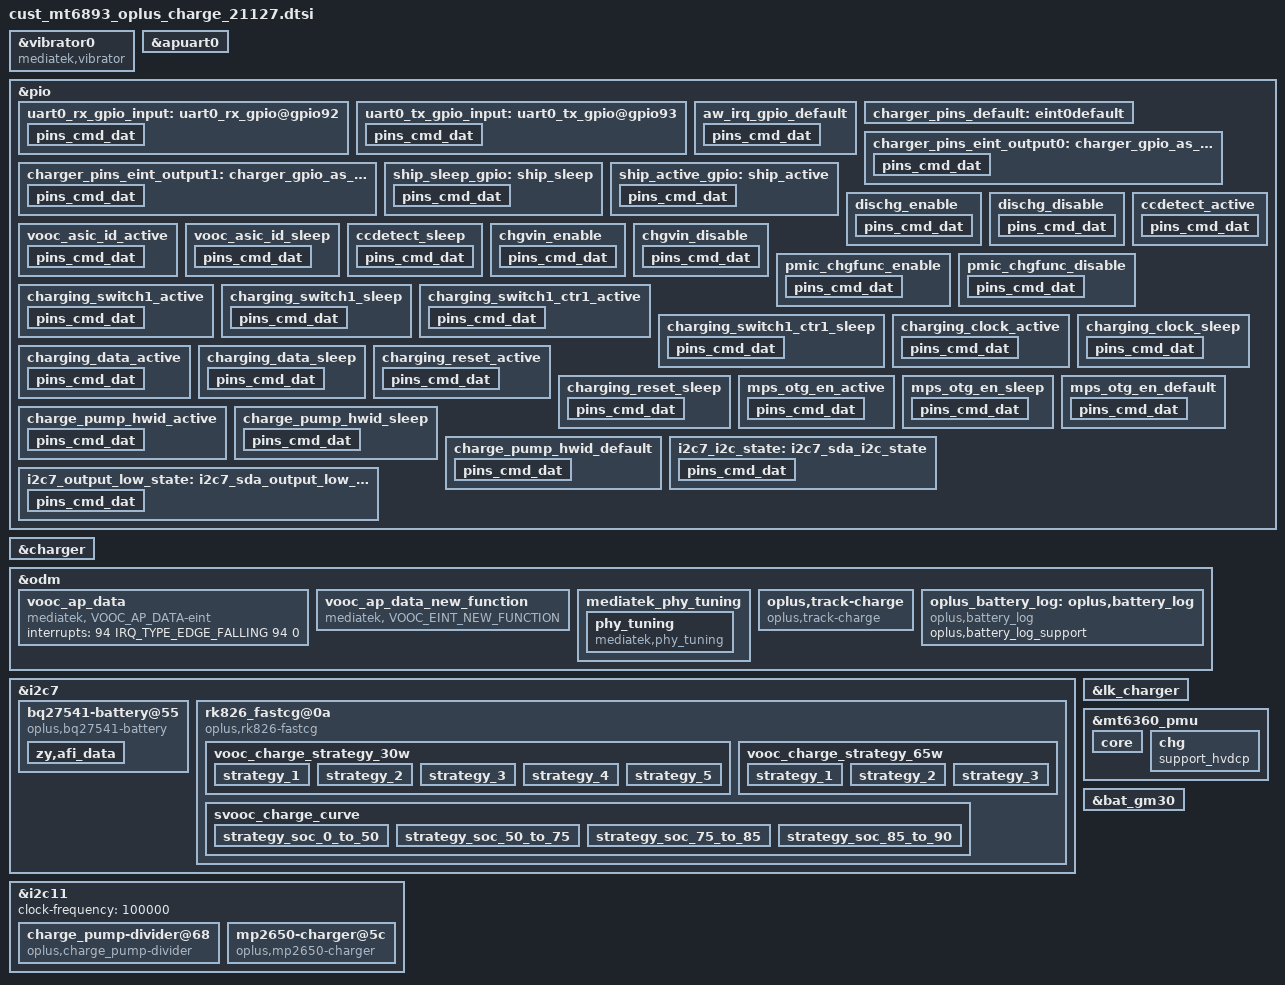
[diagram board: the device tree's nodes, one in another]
// SPDX-License-Identifier: GPL-2.0-only
/*
* Copyright (C) 2021-2020 Oplus. All rights reserved.
*/

/* charge start */
&vibrator0 {
	compatible = "mediatek,vibrator";
	vib_timer = <30>;
	vib_limit = <0>;
	vib_vol= <11>;
	lk_vib_vol  = <11>;
	status = "okay";
};

&apuart0 {
	pinctrl-names = "uart0_rx_gpio", "uart0_tx_gpio";
	pinctrl-0 = <&uart0_rx_gpio_input>;
	pinctrl-1 = <&uart0_tx_gpio_input>;
	status = "okay";
};

&pio {
	uart0_rx_gpio_input:uart0_rx_gpio@gpio92 {
		pins_cmd_dat {
			pinmux = <PINMUX_GPIO92__FUNC_GPIO92>;
			input-enable;
			slew-rate = <0>;
			bias-disable;
		};
	};

	uart0_tx_gpio_input:uart0_tx_gpio@gpio93 {
		pins_cmd_dat {
			pinmux = <PINMUX_GPIO93__FUNC_GPIO93>;
			input-enable;
			slew-rate = <0>;
			bias-disable;
		};
	};
};

&charger {
	io-channels = <&auxadc 4>,
		<&auxadc 5>;
	io-channel-names = "auxadc4-usb_temp_v_l",
		"auxadc5-usb_temp_v_r";

	pinctrl-names = "default", "charger_gpio_as_output_low", "charger_gpio_as_output_high", "ship_sleep", "ship_active",
		"dischg_enable", "dischg_disable", "chgvin_enable", "chgvin_disable", "pmic_chgfunc_enable", "pmic_chgfunc_disable",
		"ccdetect_active","ccdetect_sleep";
	pinctrl-0 = <&charger_pins_default>;
	pinctrl-1 = <&charger_pins_eint_output0>;		//USB_ON -> USB_SWITCH:(UART && USB)
	pinctrl-2 = <&charger_pins_eint_output1>;
	pinctrl-3 = <&ship_sleep_gpio>;
	pinctrl-4 = <&ship_active_gpio>;
	pinctrl-5 = <&dischg_enable>;
	pinctrl-6 = <&dischg_disable>;
	pinctrl-7 = <&chgvin_enable>;
	pinctrl-8 = <&chgvin_disable>;
	pinctrl-9 = <&pmic_chgfunc_enable>;
	pinctrl-10 = <&pmic_chgfunc_disable>;
	//pinctrl-5 = <&shortc_active_gpio>;
	pinctrl-11 = <&ccdetect_active>;
	pinctrl-12 = <&ccdetect_sleep>;

	qcom,hv_flashled_support;
	qcom,chargerid_support;
	qcom,smart_charging_screenoff;
	qcom,usbtemp_batttemp_gap = <12>;
	qcom,input_current_charger_ma = <2000>;
	qcom,pd_input_current_charger_ma = <2000>;
	qcom,qc_input_current_charger_ma = <2000>;
	qcom,input_current_usb_ma = <500>;

	qcom,input_current_led_ma = <1200>;
	qcom,input_current_led_ma_high = <1200>;
	qcom,input_current_led_ma_warm = <1500>;
	qcom,input_current_led_ma_normal = <2000>;
	qcom,led_warm_bat_decidegc = <350>;
	qcom,led_high_bat_decidegc = <370>;

	qcom,input_current_camera_ma = <1200>;
	qcom,input_current_cdp_ma = <1500>;

	qcom,input_current_vooc_led_ma_high = <2200>;
	qcom,input_current_vooc_led_ma_warm = <3200>;
	qcom,input_current_vooc_led_ma_normal = <3600>;
	qcom,input_current_vooc_ma_normal = <3600>;
	qcom,vooc_temp_bat_normal_decidegc = <350>;
	qcom,input_current_vooc_ma_warm = <3200>;
	qcom,vooc_temp_bat_warm_decidegc = <370>;
	qcom,input_current_vooc_ma_high = <2200>;
	qcom,vooc_temp_bat_hot_decidegc = <510>;

	qcom,charger_current_vooc_ma_normal = <1800>;

	qcom,chg_ctrl_by_calling;
	qcom,input_current_calling_ma = <1500>;

	qcom,overtemp_bat_decidegc = <350>;
	qcom,iterm_disabled = <0>;
	sw_full_count = <25>;
	qcom,iterm_ma = <230>;
	qcom,recharge-mv = <100>;
	qcom,batt_capacity_mah = <4500>;/*typical capacity*/

	qcom,removed_bat_decidegc = <190>;  /*<-19C*/

	qcom,cold_bat_decidegc = <100>;  /*-10C~0C*/
	qcom,temp_cold_vfloat_mv = <4438>;
	qcom,temp_cold_fastchg_current_ma = <550>;

	qcom,little_cold_bat_decidegc = <0>;    /*0C~5C*/
	qcom,temp_little_cold_vfloat_mv = <4438>;
	qcom,temp_little_cold_fastchg_current_ma_high = <1100>;
	qcom,temp_little_cold_fastchg_current_ma_low = <1100>;
	qcom,temp_little_cold_fastchg_current_ma = <1100>;
	qcom,pd_temp_little_cold_fastchg_current_ma_high = <2000>;
	qcom,pd_temp_little_cold_fastchg_current_ma_low = <1430>;
	qcom,qc_temp_little_cold_fastchg_current_ma_high = <2000>;
	qcom,qc_temp_little_cold_fastchg_current_ma_low = <1430>;

	qcom,cool_bat_decidegc = <50>;  /*5C~12C*/
	qcom,temp_cool_vfloat_mv = <4438>;
	qcom,temp_cool_fastchg_current_ma_high = <1100>;
	qcom,temp_cool_fastchg_current_ma_low = <1100>;
	qcom,pd_temp_cool_fastchg_current_ma_high = <2000>;
	qcom,pd_temp_cool_fastchg_current_ma_low = <2000>;
	qcom,qc_temp_cool_fastchg_current_ma_high = <2000>;
	qcom,qc_temp_cool_fastchg_current_ma_low = <2000>;

	qcom,little_cool_bat_decidegc = <120>;  /*12C~16C*/
	qcom,temp_little_cool_vfloat_mv = <4438>;
	qcom,temp_little_cool_fastchg_current_ma = <1100>;
	qcom,pd_temp_little_cool_fastchg_current_ma = <2000>;
	qcom,qc_temp_little_cool_fastchg_current_ma = <2000>;

	qcom,normal_bat_decidegc = <160>;       /*16C~45C*/
	qcom,temp_normal_vfloat_mv = <4438>;
	qcom,temp_normal_fastchg_current_ma = <1100>;
	qcom,pd_temp_normal_fastchg_current_ma = <2000>;
	qcom,qc_temp_normal_fastchg_current_ma = <2000>;

	qcom,warm_bat_decidegc = <450>;         /*45C~53C*/ /*8pin Bat Vooc project need add 3 degree C*/
	qcom,temp_warm_vfloat_mv = <4130>;
	qcom,temp_warm_fastchg_current_ma = <1100>;
	qcom,pd_temp_warm_fastchg_current_ma = <1210>;
	qcom,qc_temp_warm_fastchg_current_ma = <1210>;
	qcom,temp_warm_fastchg_current_ma_led_on = <500>;

	qcom,hot_bat_decidegc = <530>;

	qcom,non_standard_vfloat_mv = <3980>;
	qcom,non_standard_fastchg_current_ma = <512>;

	qcom,short_c_bat_cv_mv = <4330>;
	qcom,short_c_bat_vfloat_mv = <3800>;
	qcom,short_c_bat_fastchg_current_ma = <512>;

	qcom,cold_vfloat_sw_limit = <4385>;
	qcom,little_cold_vfloat_sw_limit = <4385>;
	qcom,cool_vfloat_sw_limit = <4385>;
	qcom,little_cool_vfloat_sw_limit = <4385>;
	qcom,normal_vfloat_sw_limit = <4385>;
	qcom,warm_vfloat_sw_limit = <4080>;
	qcom,non_standard_vfloat_sw_limit = <3930>;
	qcom,short_c_bat_vfloat_sw_limit = <3750>;

	qcom,max_chg_time_sec = <63360>; // 2200 * 2 / 250 H
	qcom,charger_hv_thr = <9900>;
	qcom,charger_recv_thr = <9500>;
	qcom,charger_lv_thr = <3400>;
	qcom,vbatt_full_thr = <4438>;
	qcom,vbatt_hv_thr = <4600>;

	qcom,vfloat_step_mv = <8>;
	qcom,non_standard_vfloat_over_sw_limit = <3990>;
	qcom,cold_vfloat_over_sw_limit = <4445>;
	qcom,little_cold_vfloat_over_sw_limit = <4445>;
	qcom,cool_vfloat_over_sw_limit = <4445>;
	qcom,little_cool_vfloat_over_sw_limit = <4445>;
	qcom,normal_vfloat_over_sw_limit = <4445>;
	qcom,warm_vfloat_over_sw_limit = <4140>;

	qcom,vbatt_power_off = <3300>;
	qcom,vbatt_soc_1 = <3310>;
	qcom,vooc_project = <7>;
	qcom,vbatt_num = <2>;
	qcom,new_ui_warning_support;
	qcom,ffc_support;
	qcom,dual_ffc;

	qcom,normal_vterm_hw_inc = <18>;
	qcom,non_normal_vterm_hw_inc = <18>;

	qcom,ff1_normal_fastchg_ma = <550>;
	qcom,ff1_warm_fastchg_ma = <550>;

	qcom,ffc2_normal_fastchg_ma = <350>;/*12C~35c*/
	qcom,ffc2_temp_warm_decidegc = <350>;
	qcom,ffc2_warm_fastchg_ma = <350>;/*35C~40c*/
	qcom,ffc2_temp_high_decidegc = <400>;
	qcom,ffc2_temp_low_decidegc = <120>;

	qcom,ff1_exit_step_ma = <150>;
	qcom,ff1_warm_exit_step_ma = <150>;
	qcom,ffc2_exit_step_ma = <150>;
	qcom,ffc2_warm_exit_step_ma = <150>;

	qcom,ffc_normal_vfloat_sw_limit = <4445>;
	qcom,ffc_temp_normal_vfloat_mv = <4500>;
	qcom,ffc_normal_vfloat_over_sw_limit = <4500>;
	qcom,ffc_warm_vfloat_sw_limit = <4445>;
	qcom,ffc_temp_warm_vfloat_mv = <4500>;
	qcom,ffc_warm_vfloat_over_sw_limit = <4500>;

	qcom,ffc2_normal_vfloat_sw_limit = <4440>;
	qcom,ffc2_temp_normal_vfloat_mv = <4500>;
	qcom,ffc2_normal_vfloat_over_sw_limit = <4500>;
	qcom,ffc2_warm_vfloat_sw_limit = <4438>;
	qcom,ffc2_temp_warm_vfloat_mv = <4500>;
	qcom,ffc2_warm_vfloat_over_sw_limit = <4500>;

	qcom,default_iterm_ma = <230>;
	qcom,default_temp_normal_fastchg_current_ma = <1100>;
	qcom,default_normal_vfloat_sw_limit = <4385>;
	qcom,default_temp_normal_vfloat_mv = <4438>;
	qcom,default_normal_vfloat_over_sw_limit = <4445>;

	qcom,default_temp_little_cool_fastchg_current_ma = <1100>;
	qcom,default_little_cool_vfloat_sw_limit = <4385>;
	qcom,default_temp_little_cool_vfloat_mv = <4438>;
	qcom,default_little_cool_vfloat_over_sw_limit = <4445>;

	qcom,vooc_show_ui_soc_decimal;
	qcom,ui_soc_decimal_speedmin = <20>;//2A
	qcom,check_batt_full_by_sw;
	qcom,external_gauge;
	qcom,chg_ctrl_by_lcd;
	qcom,chg_ctrl_by_vooc;
	qcom,chg_ctrl_by_camera;
	qcom,support_ntc_01c_precision;
	qcom,sw_vfloat_over_protect_enable;

	qcom,support_abnormal_adapter;

	//for PD9V or QC9V
	qcom,vbatt_pdqc_to_5v_thr = <4100>;
	qcom,vbatt_pdqc_to_9v_thr = <4000>;

	//GPIO config:
	qcom,chargerid_switch-gpio = <&pio 192 0x00>;
	qcom,ship-gpio = <&pio 27 0x00>;
	qcom,dischg-gpio = <&pio 51 0x00>;
	//qcom,shortc-gpio = <&pio 121 0x00>;
	qcom,ccdetect-gpio = <&pio 5 0x00>;
	qcom,chgvin = <&pio 30 0x00>;
	qcom,pmic_chgfunc = <&pio 26 0x00>;
};

&pio{
	aw_irq_gpio_default: aw_irq_gpio_default {
		pins_cmd_dat {
			pinmux = <PINMUX_GPIO8__FUNC_GPIO8>;
			input-enable;
			slew-rate = <0>;
			bias-pull-up;
		};
	};
};

&odm {
	vooc_ap_data:vooc_ap_data {
		compatible = "mediatek, VOOC_AP_DATA-eint";
		interrupts = <94 IRQ_TYPE_EDGE_FALLING 94 0>;
	};
	vooc_ap_data_new_function:vooc_ap_data_new_function {
		compatible = "mediatek, VOOC_EINT_NEW_FUNCTION";
	};

	mediatek_phy_tuning:mediatek_phy_tuning {
		phy_tuning {
			compatible = "mediatek,phy_tuning";
			eye-vrt = <6>;
			eye-term = <6>;
			eye-rev6 = <2>;
			eye-disc = <0xF>;
			host-eye-vrt = <6>;
			host-eye-term = <6>;
			host-eye-rev6 = <2>;
			host-eye-disc = <0xF>;
		};
	};

	oplus,track-charge {
		compatible = "oplus,track-charge";
		track,fast_chg_break_t_thd = <1000>;
		track,general_chg_break_t_thd = <200>;
		track,voocphy_type = <4>;
		track,wired_max_power = <80000>;
		track,wired_fast_chg_scheme = <1>;
	};

	oplus_battery_log: oplus,battery_log {
		compatible = "oplus,battery_log";
		oplus,battery_log_support;
	};
};

&i2c7 {
	status = "okay";
	clock-frequency = <100000>;

	bq27541-battery@55 {
		status = "okay";
		compatible = "oplus,bq27541-battery";
		reg = <0x55 0>;
		qcom,modify-soc-smooth;
		qcom,modify-soc-calibration;
		qcom,batt_bq28z610;
		qcom,sha1_key_index = <1>;
		//qcom,bq28z610_need_balancing;
		zy,afi_data{
			battery,name = "BLP855";
			qmax_min = <1776>;
			qmax_max = <2553>;
			static_df_checksum_3e = [38 68];			//len 2
			static_df_checksum_60 = [A3 06];			//len 2
			afi_buf_num = <7>;
			afi_buf_0 = [
				11 D0 11 17 11 D0 11 17 11 D0 11 17 11 D0 11 17 
				01 0A 8C 0A 0C 1C 25 1C 02 FF CE 02 EC 78 02 FF
				CE 05 C2 0A C2 0A 72 A3 0A 0C D1 02 0C 9F 0D 03 
				02 0C D1 0A 79 02 0A AB 09 E3 02 0A 15 07 D0 07 
				08 07 08 00 02 09 C4 07 D0 D2 F0 00 02 03 E8 05 
				11 EE 05 0E 74 00 0A 01 F4 0A 07 08 0E 74 00 0A 
				01 F4 0A 00 0A 05 FF F6 05 0A 0A AB 0B 23 0B 73 
				0B A5 0B D7 0C D1 00 0A 00 58 00 2C 11 5D 00 84 
				01 60 01 08 11 5D 07 BC 0F A4 0B B0 11 5D 09 CC 
				11 88 0D C0 11 5D 03 F4 07 BC 05 D8 09 C4 0D 48 
				0E D8 0F A0 00 01 01 2C 01 2C 01 2C 01 2C 00 4B 
				03 84 28 01 65 01 6B 03 00 00 46 50 50 00 30 00
				96 00 AF 08 AC 06 B6 1E 3C 5A
				];
			afi_buf_1 = [
				64 63 64 61 00 01 01 02 05 21 1C 00 A2 40 00 17 
				00 00 00 03 00 00 0A F0 0A 28 14 0A 14 10 E0 64 
				07 D0 00 03 0F 00 14 04 19 C8 00
				];
			afi_buf_2 = [
				AA 21 10 03 43 05 41 07 21 09 81 0B EB 0D E7 0F 
				19 11 3B 13 9E 15 FC 17 74 19 6A 1B 64 5D B2 B5 
				00 33 22 04 24 22 26 8F 28 62 2A CC 2C E4 2E 46 
				30 58 32 79 34 9F 36 1B 38 49 3A 03 7C 56 08 D7 
				08 D6 33
				];
			afi_buf_3 = [
				11 38 11 38 01 2C FE D5 FC 18 FE D5 FC 18 00 5D 
				00 32 00 32
				];
			afi_buf_4 = [38 68];
			afi_buf_5 = [
				FF 21 10 03 43 05 41 07 21 09 81 0B EB 0D E7 0F 
				19 11 3B 13 9E 15 FC 17 74 19 6A 1B 64 5D B2 E0 
				00 33 22 04 24 22 26 8F 28 62 2A CC 2C E4 2E 46 
				30 58 32 79 34 9F 36 1B 38 49 3A 03 7C 56 01 01 
				00 00 00 00 00 14 00 0F 00 46 00 3C 00 3C 01 3C 
				FF F6 FE 0C 32
				];
			afi_buf_6 = [
				2A 69 20 A8 26 82 24 64 2A 09 08 77 0E 75 0C 9B 
				12 81 10 BF 16 9D 14 F3 1A 58 FB C6 FD 47 FF 28 
				C1 35 C3 12 C5 8B C7 4D C9 2F CB C8 CD CC CF 6F 
				F1 EF F3 4E F5 69 F7 4C F9 43 FB 82 FD C5 FF 48 
				81 57 83 17 85 97 87 E8 89 A7 8B 05 8D 81 EF F7 
				31 E9 CD 75 CB 11 C9 DB 27 47 C5 3A C3 D3 C1 AB 
				FF 72 FD 95 DB B3 D9 B6 D7 39 D5 16 B3 06 B1 3F 
				8F 1B AD 05 CB DE A9 CD 78 D6 7A 0C 7C 6A 5E FC 
				80 9E A2 CA 84 37 86 BF 88 CE 35 45 D3 5A B1 77 
				AF 19 AD 08 AB 67 C9 EB E7 88 E5 E6 83 3C 20 7E 
				C0 A1 5D E5 5B CC 59 2A 57 04 55 4A 53 A1 51 C2 
				4F 7F 4D 23 4B 05 49 D9 47 68 45 20 BC F3 41 E0 
				1F 2F 1D D3 1B D6 19 34 37 EB 15 5D 13 37 11 A0 
				0F 7B 0D 9A 0B 9E 09 F0 07 59 05 38 03 88 FE 5A 
				E0 E1 E2 20 E4 26 E6 FE C8 6C 8A EB AC AC ED EB 
				90 10 B3 F3 78 F5 B6 D4 E1 38 46 3A 50 DD EC FF 
				8C 21 62 A3 A4 A1 CE 07 8A 05 4B 28 09 81 4E 04 
				10 51 12 13 75 02 36 92 5E 5F 5B 5B 7C 5D 5F 5E 
				61 67 E3 83 A4 CA 86 A5 28 30 6A BC EC 2D 2E AD 
				54 31 2B 73 E9 16 BA 76 58 69 DC FB 93 3D 3E DE 
				B0 41 A3 A3 3C 45 46 47 48 49 A7 2A 05 4D E2 6E 
				19 51 B7 73 7D 55 B7 57 70 59 B9 BA 14 5D 5E 5F 
				60 61 62 63 64 65 C7 86 21 69 4B AA A4 6D 6E 6F 
				70 71 72 73 74 75 76 77 78 79 7A 7B 7C 7D 7E 7F 
				80 01 02 83 E4 C5 C6 87 C8 89 8A 8B 8C 8D 4F 8D 
				90 9E FC 99 D4 74 B6 85 98 80 9A 82 1C 9D 5D FF 
				A0 2D A2 FC 04 29 A6 BE C8 89 61 AB F3 2F 8E BD 
				15 3D 12 F8 14 B5 B6 B7 0C B2 0C E4 0A 5F 01 2C
				];
		};
	};

	rk826_fastcg@0a{
		status = "okay";
		compatible = "oplus,rk826-fastcg";
		reg = <0x0a 0>;
		qcom,oplus_batt_4250mv;
		qcom,support_vooc_by_normal_charger_path;
		qcom,vooc-version = <5>;
		qcom,vooc_fw_update_newmethod;
		qcom,smart_chg_bcc_support;
		qcom,vooc-fw-type = <3>;
		qcom,vooc_reply_mcu_bits = <7>;
		qcom,vooc-low-temp = <0>;
		qcom,vooc-high-temp = <500>;
		qcom,vooc-low-soc = <1>;
		qcom,vooc-high-soc = <90>;
		qcom,vooc-cool-temp = <120>;
		qcom,vooc-little-cool-temp = <200>;
		qcom,vooc-normal-low-temp = <350>;
		qcom,vooc-normal-high-temp = <440>;
		qcom,vooc-warm-allow-vol = <4000>;
		qcom,vooc-warm-allow-soc = <50>;
		qcom,vooc-little-cool-to-normal-temp = <180>;
		qcom,vooc-normal-to-little-cool-current = <0x05>;//5A

		qcom,vooc_cool_bat_volt = <3450>;
		qcom,vooc_little_cool_bat_volt = <3400>;
		qcom,vooc_normal_bat_volt = <3350>;
		qcom,vooc_warm_bat_volt = <3300>;

		qcom,vooc_cool_bat_suspend_volt = <3450>;
		qcom,vooc_little_cool_bat_suspend_volt = <3400>;
		qcom,vooc_normal_bat_suspend_volt = <3350>;
		qcom,vooc_warm_bat_suspend_volt = <3300>;

		qcom,vooc_multistep_adjust_current_support;
		qcom,vooc_multistep_initial_batt_temp = <1000>;
		qcom,vooc_strategy_normal_current = <0x0f>;
		qcom,vooc_batt_over_high_temp = <510>;
		qcom,vooc_batt_over_low_temp = <45>;
		qcom,vooc_over_high_or_low_current = <0x0>;

		qcom,vooc_strategy1_batt_high_temp0 = <400>;
		qcom,vooc_strategy1_batt_high_temp1 = <420>;
		qcom,vooc_strategy1_batt_high_temp2 = <430>;
		qcom,vooc_strategy1_batt_low_temp2 = <420>;
		qcom,vooc_strategy1_batt_low_temp1 = <410>;
		qcom,vooc_strategy1_batt_low_temp0 = <390>;

		qcom,vooc_strategy1_high_current0 = <0x09>;  // 5A
		qcom,vooc_strategy1_high_current1 = <0x07>;  // 4A
		qcom,vooc_strategy1_high_current2 = <0x05>;  // 3A
		qcom,vooc_strategy1_low_current2 = <0x07>;   // 4A
		qcom,vooc_strategy1_low_current1 = <0x09>;   // 5A
		qcom,vooc_strategy1_low_current0 = <0x0c>;   // 0x0c

		qcom,vooc_strategy2_batt_up_temp1 = <375>;
		qcom,vooc_strategy2_batt_up_down_temp2 = <380>;
		qcom,vooc_strategy2_batt_up_temp3 = <390>;
		qcom,vooc_strategy2_batt_up_down_temp4 = <400>;
		qcom,vooc_strategy2_batt_up_temp5 = <410>;
		qcom,vooc_strategy2_batt_up_temp6 = <415>;
		qcom,vooc_strategy2_high0_current = <0x09>;
		qcom,vooc_strategy2_high1_current = <0x07>;
		qcom,vooc_strategy2_high2_current = <0x05>;
		qcom,vooc_strategy2_high3_current = <0x03>;

		qcom,abnormal_adapter_current = <0x00 0x00 0x09 0x09 0x07 0x07 0x05 0x05 0x03 0x03>;

		qcom,vooc_current_lvl = <1000
									1500
									2000
									2500
									3000
									3500
									4000
									4500
									5000
									5500
									6000
									6500
									7000
									7500
									8000
									8500
									9000
									9500
									10000
									10500
									11000
									11500
									12000
									12500>;
		pinctrl-names = "switch1_act_switch2_act", "switch1_sleep_switch2_sleep",
						"switch1_act_switch3_act", "switch1_sleep_switch3_sleep",
						"switch1_act_switch2_sleep", "switch1_sleep_switch2_act",
						"clock_active","clock_sleep",
						"data_active","data_sleep",
						"reset_active","reset_sleep",
						"charging_switch1_ctr1_active","charging_switch1_ctr1_sleep",
						"vooc_asic_id_active","vooc_asic_id_sleep";
		pinctrl-0 = <&charging_switch1_active>;
		pinctrl-1 = <&charging_switch1_sleep>;
		pinctrl-2 = <&charging_switch1_active>;
		pinctrl-3 = <&charging_switch1_sleep>;
		pinctrl-4 = <&charging_switch1_active>;
		pinctrl-5 = <&charging_switch1_sleep>;
		pinctrl-6 = <&charging_clock_active>;
		pinctrl-7 = <&charging_clock_sleep>;
		pinctrl-8 = <&charging_data_active>;
		pinctrl-9 = <&charging_data_sleep>;
		pinctrl-10 = <&charging_reset_active>;
		pinctrl-11 = <&charging_reset_sleep>;
		pinctrl-12 = <&charging_switch1_ctr1_active>;
		pinctrl-13 = <&charging_switch1_ctr1_sleep>;
		pinctrl-14 = <&vooc_asic_id_active>;
		pinctrl-15 = <&vooc_asic_id_sleep>;

		qcom,charging_switch1-gpio = <&pio 191 0x00>;
		qcom,charging_switch1_ctr1-gpio = <&pio 163 0x00>;
		//qcom,charging_switch2-gpio = <&tlmm 113 0x00>;
		//qcom,charging_switch3-gpio = <&tlmm 38 0x00>;

		qcom,charging_reset-gpio = <&pio 189 0x00>;
		qcom,charging_clock-gpio = <&pio 95 0x00>;
		qcom,charging_data-gpio = <&pio 94 0x00>;
		qcom,vooc_asic_id-gpio = <&pio 187 0x00>;

		qcom,parse_fw_from_dt;
		vooc,firmware_data = [
00 00 34 55 68 38 00 00 64 00 00 00 64 00 00 00 60 48 14 77 98 bb a1 7e 00 00 00 00 00 00 00 00

00 00 00 00 00 00 00 00 00 00 00 00 00 00 00 00 00 00 00 00 00 00 00 00 00 00 00 00 00 00 00 00

00 00 00 00 00 00 00 00 00 00 00 00 00 00 00 00 00 00 00 00 00 00 00 00 00 00 00 00 00 00 00 00

00 00 00 00 00 00 00 00 00 00 00 00 00 00 00 00 00 00 00 00 00 00 00 00 00 00 00 00 00 00 00 00

00 08 00 20 0d 01 00 21 a9 09 00 21 79 09 00 21 00 00 00 00 00 00 00 00 00 00 00 00 00 00 00 00

00 00 00 00 00 00 00 00 00 00 00 00 2b 0a 00 21 00 00 00 00 00 00 00 00 29 0a 00 21 2d 0a 00 21

2f 01 00 21 11 09 00 21 2f 01 00 21 31 0a 00 21 2f 01 00 21 2f 01 00 21 2f 01 00 21 2f 01 00 21

49 0b 00 21 2f 01 00 21 2f 01 00 21 2f 01 00 21 03 48 85 46 00 f0 dc fb 00 48 00 47 ad 20 00 21

00 08 00 20 40 1e fd d8 70 47 00 00 08 48 09 49 01 60 08 20 c0 00 01 20 80 f3 10 88 00 bf 00 bf

05 48 00 47 fe e7 fe e7 fe e7 fe e7 fe e7 fe e7 00 00 02 50 00 80 00 80 f1 00 00 21 30 b5 0b 46

01 46 00 20 20 22 01 24 09 e0 0d 46 d5 40 9d 42 05 d3 1d 46 95 40 49 1b 25 46 95 40 40 19 15 46

52 1e 00 2d f1 dc 30 bd 70 b5 00 24 25 46 00 28 01 da 01 24 40 42 00 29 01 da 01 25 49 42 ff f7

dd ff ac 42 00 d0 40 42 00 2c 00 d0 49 42 70 bd f8 b5 02 46 4a 40 d4 0f 42 00 4b 00 52 08 5b 08

9a 42 02 d2 02 46 08 46 11 46 4a 00 23 d0 c3 0d 4a 00 dd b2 12 0e ad 1a 20 2d 35 da 49 02 01 26

49 0a f6 05 8a 19 00 2c 00 d0 52 42 20 21 4f 1b 11 46 b9 40 2a 41 10 18 c2 0d 9a 42 21 d0 00 2c

17 d0 01 2d 08 dc da 05 80 1a d2 0f 80 19 d2 07 db b2 00 f0 c4 fa f8 bd da 05 80 1a 01 23 40 00

1b 06 c0 18 80 18 5a 42 80 18 ca 0f 10 43 49 00 07 e0 49 08 c2 07 11 43 da 05 80 1a 80 19 40 08

80 18 00 f0 a4 fa f8 bd 61 00 01 22 51 1a 00 1b f7 e7 01 22 d2 07 51 40 aa e7 01 22 d2 07 50 40

a6 e7 02 46 70 b5 4a 40 d3 0f db 07 40 00 2d d0 4a 00 2a d0 01 0e 14 0e 00 02 12 02 09 19 40 0a

52 0a 84 18 e5 01 04 46 54 43 00 0a 12 0a 2e 04 50 43 a4 19 42 19 20 0c c5 43 aa 18 12 0c 01 25

ad 03 52 1c 52 19 12 04 7f 39 24 04 00 d0 52 1c 10 43 01 d4 40 00 49 1e c2 b2 0c 06 c0 09 20 18

40 1c 40 08 80 2a 02 d0 03 e0 00 20 70 bd 40 08 40 00 00 29 00 da 00 20 18 43 70 bd 70 b5 02 46

4a 40 d5 0f 40 00 4a 00 ed 07 40 08 52 08 00 28 14 d0 00 2a 12 d0 c4 0d d3 0d 41 02 01 20 c0 05

52 02 49 0a 52 0a e4 1a 09 18 12 18 7d 34 91 42 01 d3 64 1c 00 e0 49 00 00 2c 01 da 00 20 70 bd

00 23 91 42 01 d3 89 1a 03 43 40 08 49 00 00 28 f7 d1 00 29 0a d0 91 42 02 d1 01 21 c9 07 05 e0

91 42 01 d2 01 21 01 e0 01 21 c9 43 e0 05 c0 18 40 19 00 f0 1c fa 70 bd f0 b5 07 46 08 46 58 40

87 b0 c0 0f 04 90 48 00 0e 46 59 00 40 08 49 08 bc 1a 88 41 05 d2 38 46 31 46 1e 46 17 46 0b 46

02 46 58 00 40 08 10 43 4c d0 30 0d 03 90 40 05 59 00 40 0d 49 0d 05 90 40 1a 02 90 40 28 72 da

18 03 01 21 00 0b 09 05 08 43 01 90 04 98 00 92 00 28 05 d0 01 99 52 42 00 20 88 41 00 92 01 90

02 98 40 21 0a 1a 01 99 00 98 00 f0 bd f9 05 46 0c 46 6b 46 07 cb 00 f0 c7 f9 c0 19 71 41 03 9a

0e 0d 00 23 d7 17 56 40 1a 46 7a 40 16 43 44 d0 04 9a 00 2a 2d d0 02 9a 01 2a 03 9a 15 dc 12 05

c0 1a 91 41 01 26 36 05 00 1c 71 41 d2 0f 05 9e d2 07 00 93 01 92 02 96 2a 46 23 46 00 f0 05 fa

07 b0 f0 bd 38 46 31 46 fa e7 16 05 22 4a 0f 46 b2 18 c0 1a b7 41 01 21 09 05 00 1c 4f 41 00 18

7f 41 11 46 18 18 79 41 e2 0f 10 43 6d 19 64 41 13 e0 e2 07 6d 08 15 43 64 08 c2 07 14 43 03 9a

01 26 12 05 c0 1a 91 41 36 05 00 1c 71 41 ce 07 40 08 30 43 49 08 c0 18 51 41 2a 46 23 46 00 f0

c7 f9 cd e7 ff e7 04 98 01 22 40 00 c1 17 12 1a 00 23 8b 41 04 98 31 46 c4 17 38 1a a1 41 ee e7

30 b4 01 24 e4 07 63 40 30 bc 55 e7 30 b4 01 24 e4 07 61 40 30 bc 4f e7 00 00 e0 ff f0 b5 1f b4

88 b0 0b 99 09 98 00 24 48 40 09 99 c0 0f 49 00 49 08 09 91 c0 07 0b 99 00 90 49 00 49 08 0b 91

09 99 08 98 a6 46 08 43 1c d0 0b 99 0a 98 08 43 18 d0 09 98 01 24 40 00 42 0d 48 00 41 0d 09 98

24 05 00 03 00 0b 20 43 09 90 0b 98 00 03 00 0b 20 43 0b 90 50 18 1c 49 40 18 00 22 01 90 14 46

10 46 05 e0 00 20 01 46 0d b0 f0 bd 03 28 01 da 03 46 00 e0 03 23 9c 46 c1 1a 0a ae 0a e0 5f 00

08 ad ed 5b 4f 00 f7 5b 7d 43 00 27 aa 18 7c 41 49 1c 5b 1e 61 45 f2 dd 41 00 04 ab 5a 52 21 04

12 0c 0a 43 24 0c 40 1c 08 28 df db 01 98 02 90 00 99 70 46 01 91 00 90 05 9b 04 9a 07 99 06 98

00 f0 53 f9 d0 e7 00 00 0d fc ff ff f0 b5 0c 46 5c 40 85 b0 e4 0f e4 07 03 94 4c 00 00 26 64 08

59 00 94 46 49 08 02 46 02 96 22 43 21 d0 62 46 0a 43 1e d0 62 00 57 0d 4a 00 0e 03 23 03 55 0d

01 24 02 46 2c 49 24 05 78 1b 1b 0b 36 0b 40 18 23 43 26 43 61 46 00 90 1c 46 50 1a b4 41 03 d3

00 98 40 1c 00 90 02 e0 92 18 00 98 5b 41 00 28 03 da 00 20 01 46 05 b0 f0 bd 00 20 01 21 09 05

07 46 86 46 11 e0 64 46 1d 46 14 1b b5 41 06 d3 65 46 52 1b b3 41 74 46 07 43 0c 43 a6 46 cd 07

40 08 49 08 28 43 92 18 5b 41 05 46 0d 43 ea d1 10 46 18 43 13 d0 60 46 19 46 50 40 71 40 08 43

06 d0 60 46 10 1a b3 41 06 d2 01 22 00 23 06 e0 00 22 01 23 db 07 02 e0 01 22 d2 43 53 10 00 98

74 46 01 05 38 1c 61 41 02 9c 03 9d 00 19 69 41 00 f0 ce f8 bf e7 00 00 fd 03 00 00 c2 17 c1 0f

50 40 10 b5 40 18 ca 07 96 23 00 21 00 f0 87 f8 10 bd 10 b5 00 22 96 23 11 46 00 f0 80 f8 10 bd

c2 0f 41 00 40 02 01 23 40 0a db 05 d2 07 09 0e c0 18 7f 29 01 da 00 20 70 47 96 29 03 dc 96 23

59 1a c8 40 01 e0 96 39 88 40 00 2a f4 d0 40 42 70 47 c2 0f d2 07 40 00 40 08 0b d0 c1 0d 07 23

db 01 c9 18 40 02 09 05 40 0a 11 43 c2 08 40 07 11 43 70 47 00 20 01 46 70 47 cb 0f db 07 49 00

10 b5 49 08 02 46 0a 43 07 d0 0a 0d 07 24 09 03 e4 01 09 0b 12 1b 00 2a 01 dc 00 20 10 bd c9 00

44 0f 0c 43 c1 00 e0 18 d2 05 80 18 00 f0 2f f8 10 bd 00 00 01 22 d2 07 00 28 00 db 10 1a 00 29

00 db 51 1a 81 42 70 47 10 b5 20 2a 04 db 01 46 20 3a 91 40 00 20 10 bd 91 40 20 23 9c 1a 03 46

e3 40 19 43 90 40 10 bd 10 b5 20 2a 06 db cb 17 08 46 20 3a 10 41 c1 17 0b 43 06 e0 0b 46 13 41

d0 40 20 24 a2 1a 91 40 08 43 19 46 10 bd 00 29 04 da 40 1c 49 00 01 d1 40 08 40 00 70 47 70 b4

00 24 05 0c 05 d1 10 24 00 04 02 d1 00 29 21 d0 11 24 05 0e 01 d1 00 02 08 34 05 0f 01 d1 00 01

24 1d 85 0f 01 d1 80 00 a4 1c 00 28 01 db 40 00 64 1c 00 29 08 d0 20 25 2e 1b 0d 46 f5 40 a1 40

00 d0 01 21 29 43 08 43 01 06 1b 1b 00 0a db 1d 02 d5 00 20 70 bc 70 47 db 05 18 18 80 18 00 29

f8 da 40 1c 49 00 f5 d1 70 bc 40 08 40 00 70 47 10 b5 00 2b 08 da 00 24 40 1c 61 41 92 18 5b 41

1a 43 01 d1 40 08 40 00 10 bd f0 b5 1f b4 82 b0 05 46 0c 00 03 d0 08 46 00 f0 a2 f9 02 e0 00 f0

9f f9 20 30 02 46 00 90 21 46 28 46 ff f7 7c ff 04 9b 05 9a 04 46 0f 46 18 43 11 43 08 43 14 d0

18 46 10 43 1b d0 00 98 40 21 0a 1a 18 46 05 99 00 f0 40 f8 05 46 0e 46 00 9a 05 99 04 98 ff f7

63 ff 08 43 05 d0 01 20 04 e0 20 46 39 46 07 b0 f0 bd 00 20 c1 17 05 43 0e 43 2c 43 37 43 00 99

0e 98 63 05 40 1a 79 05 e4 0a 00 22 0c 43 fd 0a 0a 30 02 d5 00 20 01 46 e9 e7 01 05 10 19 69 41

0c 9c 0d 9d 00 19 69 41 ff f7 a2 ff df e7 00 00 06 4c 01 25 06 4e 05 e0 e3 68 07 cc 2b 43 0c 3c

98 47 10 34 b4 42 f7 d3 ff f7 16 fc 54 38 00 21 64 38 00 21 10 b5 20 2a 04 db 08 46 20 3a d0 40

00 21 10 bd 0b 46 d3 40 d0 40 20 24 a2 1a 91 40 08 43 19 46 10 bd 10 b5 04 46 20 01 00 09 ff f7

01 fc 10 bd 00 bf 01 46 40 1e 00 29 fb d1 70 47 10 b5 02 f0 63 f9 04 46 80 20 20 40 00 28 18 d0

80 20 02 f0 55 f9 10 48 00 78 00 28 07 d1 02 f0 9f fc 00 20 0d 49 08 70 01 20 0b 49 08 70 0c 48

00 78 02 28 02 d1 00 f0 3f f9 0c e0 00 f0 04 fd 09 e0 40 20 20 40 00 28 05 d0 40 20 02 f0 38 f9

01 20 04 49 08 70 10 bd 71 01 00 20 38 01 00 20 5f 01 00 20 11 01 00 20 00 bf fe e7 70 b5 04 46

0d 46 16 46 2b 46 32 46 21 46 55 20 02 f0 e8 f9 70 bd 70 b5 04 46 0d 46 16 46 2b 46 32 46 21 46

55 20 02 f0 7b fa 70 bd 70 47 00 00 70 b5 00 21 00 23 0f 22 c4 78 00 2c 25 d0 19 4c e4 68 07 25

2d 02 2c 40 2c 1b 21 0a 04 24 63 1a 14 46 cc 40 22 46 44 78 9c 40 21 46 84 78 14 40 21 43 09 01

10 4c 03 25 2d 02 64 19 05 78 ad 00 61 51 04 78 e5 06 ed 0e 01 24 ac 40 05 78 6d 11 ad 00 09 4e

ad 19 2c 60 0a e0 04 78 e5 06 ed 0e 01 24 ac 40 04 4d 80 35 06 78 76 11 b6 00 ac 51 70 bd 00 00

00 ed 00 e0 00 e1 00 e0 70 47 70 47 70 47 00 00 10 b5 00 20 02 f0 d6 fa 37 48 00 88 00 28 05 d0

35 48 00 88 40 1e 34 49 08 80 15 e0 7d 20 c0 00 31 49 08 80 31 48 00 88 00 28 04 d0 2f 48 00 88

40 1e 2e 49 08 80 2e 48 00 88 00 28 04 d0 2c 48 00 88 40 1e 2a 49 08 80 2a 48 00 68 00 28 04 d0

28 48 00 68 40 1e 27 49 08 60 27 48 00 68 00 28 04 d0 25 48 00 68 40 1e 23 49 08 60 23 48 00 68

00 28 04 d0 21 48 00 68 40 1e 20 49 08 60 20 48 00 78 00 28 04 d0 1e 48 00 78 40 1e 1c 49 08 70

1c 48 00 68 00 28 04 d0 1a 48 00 68 40 1e 19 49 08 60 19 48 00 68 00 28 04 d0 17 48 00 68 40 1e

15 49 08 60 15 48 00 78 40 1c 14 49 08 70 08 46 00 78 c8 28 0e dd 00 20 08 70 11 48 00 78 00 28

05 d0 00 20 01 f0 6c fa 01 20 0e 49 08 70 01 20 0b 49 08 70 10 bd 00 00 3a 01 00 20 3c 01 00 20

3e 01 00 20 40 01 00 20 44 01 00 20 48 01 00 20 4c 01 00 20 50 01 00 20 54 01 00 20 38 01 00 20

24 01 00 20 10 01 00 20 04 48 00 69 00 28 04 d0 01 20 02 49 48 61 76 20 c8 60 70 47 00 00 01 40

20 21 02 0c 01 d0 10 21 10 46 02 0a 01 d0 10 46 08 39 02 09 01 d0 10 46 09 1f 82 08 01 d0 10 46

89 1e 42 08 01 d0 88 1e 70 47 08 1a 70 47 30 b4 74 46 64 1e 25 78 64 1c ab 42 04 d3 63 5d 5b 00

e3 18 30 bc 18 47 1d 46 f8 e7 02 e0 08 c8 12 1f 08 c1 00 2a fa d1 70 47 70 47 00 20 01 e0 01 c1

12 1f 00 2a fb d1 70 47 10 b5 fe 48 00 78 08 28 0b da 01 f0 1b fa fc 49 fa 4a 12 78 88 54 f9 48

00 78 40 1c f7 49 08 70 10 bd f6 48 00 78 08 28 29 d1 09 20 f3 49 08 70 02 f0 86 fa f2 48 00 78

01 28 21 d1 f0 48 40 78 00 28 1d d1 ee 48 80 78 01 28 19 d1 ec 48 c0 78 c0 00 eb 49 09 79 89 00

08 43 e9 49 49 79 49 00 08 43 e7 49 89 79 08 43 e6 49 08 70 00 20 e6 49 08 70 e6 48 00 78 00 28

d6 d1 e5 49 08 70 8f e0 df 48 00 78 01 28 20 d1 dd 48 40 78 00 28 1c d1 db 48 80 78 00 28 18 d1

d9 48 c0 78 c0 00 d8 49 09 79 89 00 08 43 d6 49 49 79 49 00 08 43 d4 49 89 79 08 43 d3 49 08 70

00 20 d3 49 08 70 d3 49 08 70 02 20 d2 49 08 70 6a e0 cd 48 40 78 01 28 21 d1 cb 48 80 78 00 28

1d d1 c9 48 c0 78 01 28 19 d1 c7 48 00 79 c0 00 c5 49 49 79 89 00 08 43 c3 49 89 79 49 00 08 43

c1 49 c9 79 08 43 c1 49 08 70 00 20 c0 49 08 70 c0 48 00 78 00 28 01 d1 bf 49 08 70 84 e7 ba 48

40 78 01 28 20 d1 b8 48 80 78 00 28 1c d1 b6 48 c0 78 00 28 18 d1 b4 48 00 79 c0 00 b2 49 49 79

89 00 08 43 b0 49 89 79 49 00 08 43 ae 49 c9 79 08 43 ae 49 08 70 00 20 ad 49 08 70 ad 49 08 70

02 20 ad 49 08 70 5f e7 a7 48 c0 78 c0 00 a6 49 09 79 89 00 08 43 a4 49 49 79 49 00 08 43 a2 49

89 79 08 43 a1 49 08 70 02 20 a3 49 08 70 a0 48 00 78 00 28 05 d1 9e 48 00 78 40 1c 9c 49 08 70

02 e0 01 20 9d 49 08 70 9d 48 00 78 00 28 14 d1 9c 49 c8 70 08 71 48 71 88 71 c8 71 08 72 48 72

99 48 00 78 02 28 09 d1 90 48 00 78 00 07 00 0e 96 49 08 70 01 20 93 49 48 71 41 e2 92 48 00 78

01 28 0a d1 91 48 00 78 88 49 09 78 08 43 8f 49 08 70 01 20 8b 49 48 71 32 e2 8d 48 00 78 05 28

16 d1 88 48 80 7a 87 49 c8 70 08 46 c0 7a 08 71 08 46 00 7b 48 71 08 46 40 7b 88 71 08 46 80 7b

c8 71 08 46 c0 7b 08 72 08 46 00 7c 48 72 17 e2 7f 48 00 78 04 28 09 d1 74 48 00 78 00 07 00 0c

7c 49 08 80 01 20 77 49 48 71 09 e2 78 48 00 78 03 28 0b d1 6d 48 00 78 00 02 76 49 09 88 08 43

74 49 08 80 01 20 6f 49 48 71 f9 e1 70 48 00 78 02 28 0b d1 65 48 00 78 00 01 6e 49 09 88 08 43

6c 49 08 80 01 20 67 49 48 71 e9 e1 68 48 00 78 01 28 15 d1 67 48 00 88 5c 49 09 78 08 43 65 49

08 80 00 f0 a3 fb 01 20 5e 49 48 71 62 48 00 88 60 49 09 88 88 42 90 d1 01 20 60 49 08 70 cf e1

5f 48 00 78 00 28 4c d0 5d 48 00 78 40 1e c1 00 08 1a 5c 49 09 68 08 5c 52 49 c8 70 58 48 00 78

40 1e c1 00 08 1a 57 49 09 68 40 18 40 78 4d 49 08 71 53 48 00 78 40 1e c1 00 08 1a 51 49 09 68

40 18 80 78 47 49 48 71 4d 48 00 78 40 1e c1 00 08 1a 4c 49 09 68 40 18 c0 78 42 49 88 71 48 48

00 78 40 1e c1 00 08 1a 46 49 09 68 40 18 00 79 3c 49 c8 71 42 48 00 78 40 1e c1 00 08 1a 41 49

09 68 40 18 40 79 37 49 08 72 3d 48 00 78 40 1e c1 00 08 1a 3b 49 09 68 40 18 80 79 31 49 48 72

7e e1 2a 48 00 78 09 28 0c d1 00 20 2e 49 08 70 2f 49 08 70 32 49 08 70 01 f0 52 f8 01 20 32 49

08 70 51 e6 00 20 28 49 08 70 29 49 08 70 2c 49 08 70 1e 48 00 78 03 00 ff f7 19 fe 10 ee 09 84

a0 d6 ef 20 20 20 20 20 20 f7 eb ea e9 20 27 48 00 78 00 28 13 d0 26 48 00 78 00 28 06 d1 01 20

18 49 c8 70 08 71 08 72 48 72 02 e0 01 20 15 49 88 71 1f 48 00 78 c0 43 1d 49 08 70 3f e1 1d 48

00 78 00 28 38 d0 01 20 0e 49 c8 70 08 71 48 71 88 71 c8 71 08 72 48 72 16 48 00 78 40 1e 15 49

08 70 2c e1 21 01 00 20 19 01 00 20 23 01 00 20 15 01 00 20 60 01 00 20 5f 01 00 20 12 01 00 20

22 01 00 20 84 01 00 20 25 01 00 20 26 01 00 20 28 01 00 20 2c 01 00 20 2e 01 00 20 30 01 00 20

29 01 00 20 00 01 00 20 18 01 00 20 37 01 00 20 5e 01 00 20 58 01 00 20 b0 48 00 68 b0 49 88 42

01 da 00 24 07 e0 ad 49 09 68 ad 4a 88 1a 0a 21 ff f7 9a f8 04 46 60 06 c0 0f aa 49 c8 70 a0 06

c0 0f 08 71 e0 06 c0 0f 48 71 20 07 c0 0f 88 71 60 07 c0 0f c8 71 a0 07 c0 0f 08 72 e0 07 c0 0f

48 72 dc e0 03 21 49 03 05 20 00 03 02 f0 ca fa 9d 49 08 70 08 46 00 78 02 28 03 d1 01 20 99 49

08 71 0a e0 98 48 00 78 01 28 03 d1 95 49 08 71 48 71 02 e0 01 20 93 49 48 71 c0 e0 01 20 93 49

08 70 93 48 00 78 40 06 c0 0f 8e 49 c8 70 90 48 00 78 80 06 c0 0f 08 71 8d 48 00 78 c0 06 c0 0f

48 71 8b 48 00 78 00 07 c0 0f 88 71 88 48 00 78 40 07 c0 0f c8 71 86 48 00 78 80 07 c0 0f 08 72

83 48 00 78 c0 07 c0 0f 48 72 00 20 81 49 08 70 7f 48 00 78 64 21 48 43 ff 30 2d 30 7e 49 08 80

0a 20 7e 49 08 70 8a e0 7d 48 00 78 00 28 07 d0 00 20 7c 49 08 70 7a 48 00 78 40 1e 78 49 08 70

78 48 00 78 6f 49 c8 70 01 20 48 71 77 e0 3e e0 3c e0 22 e0 09 e0 00 e0 37 e0 03 20 72 49 08 70

01 20 68 49 08 71 88 71 69 e0 70 48 00 78 00 28 03 d0 6f 48 00 78 00 28 00 d1 60 e0 6b 48 00 78

40 1e 6a 49 08 70 06 20 6a 49 08 70 00 f0 8e ff 69 49 08 70 00 f0 c0 f9 51 e0 68 48 00 78 40 1c

67 49 08 70 65 48 00 78 80 1c 66 49 08 70 66 48 00 78 54 49 c8 70 65 48 00 78 08 71 64 48 00 78

48 71 64 48 00 78 88 71 39 e0 01 e0 00 e0 00 bf 61 48 00 78 00 28 2f d0 4c 48 00 78 00 28 2b d0

5e 48 00 78 03 28 03 d1 01 20 5d 49 08 70 0b e5 5a 48 00 78 40 1c 59 49 08 70 40 49 09 68 40 4a

88 1a 0a 21 fe f7 c0 ff 04 46 60 06 c0 0f 3d 49 c8 70 a0 06 c0 0f 08 71 e0 06 c0 0f 48 71 20 07

c0 0f 88 71 60 07 c0 0f c8 71 a0 07 c0 0f 08 72 e0 07 c0 0f 48 72 02 e0 01 f0 ee ff e4 e4 00 bf

30 49 48 4a 12 78 88 5c 01 f0 76 ff 45 48 00 78 40 1c 44 49 08 70 08 46 00 78 09 28 4c dd 04 20

00 f0 ae fa 05 20 00 f0 ab fa 01 f0 4f ff 00 20 3c 49 08 70 3c 49 08 70 3c 49 08 70 2a 48 00 78

00 28 05 d0 28 48 00 78 40 1e 27 49 08 70 33 e0 28 48 00 78 00 28 05 d0 26 48 00 78 40 1e 25 49

08 70 29 e0 26 48 00 78 00 28 0a d0 24 48 00 78 40 1e 23 49 08 70 23 48 00 78 40 1e 21 49 08 70

1a e0 2b 48 00 78 02 28 02 d0 04 28 13 d1 0a e0 0d 48 00 78 01 28 05 d1 12 48 00 78 01 28 01 d1

00 f0 8e fe 07 e0 01 20 11 49 08 70 00 f0 de fe 20 49 08 70 00 bf 00 bf 00 bf 85 e4 0c 01 00 20

4c 0d 00 00 84 01 00 20 70 01 00 20 14 01 00 20 59 01 00 20 58 01 00 20 62 01 00 20 64 01 00 20

60 01 00 20 17 01 00 20 25 01 00 20 27 01 00 20 34 01 00 20 28 01 00 20 36 01 00 20 04 01 00 20

29 01 00 20 2a 01 00 20 06 01 00 20 07 01 00 20 08 01 00 20 09 01 00 20 67 01 00 20 16 01 00 20

13 01 00 20 22 01 00 20 21 01 00 20 24 01 00 20 23 01 00 20 35 01 00 20 10 b5 5d 48 00 78 08 28

0b da 00 f0 53 fe 5b 49 59 4a 12 78 88 54 58 48 00 78 40 1c 56 49 08 70 10 bd 55 48 00 78 08 28

61 d1 09 20 52 49 08 70 01 f0 be fe 51 48 00 78 01 28 1b d1 4f 48 40 78 00 28 17 d1 4d 48 80 78

01 28 13 d1 4b 48 c0 78 c0 00 4a 49 09 79 89 00 08 43 48 49 49 79 49 00 08 43 46 49 89 79 08 43

45 49 08 70 00 20 45 49 08 70 3c e0 41 48 40 78 01 28 1b d1 3f 48 80 78 00 28 17 d1 3d 48 c0 78

01 28 13 d1 3b 48 00 79 c0 00 3a 49 49 79 89 00 08 43 38 49 89 79 49 00 08 43 36 49 c9 79 08 43

35 49 08 70 00 20 35 49 08 70 b5 e7 31 48 c0 78 c0 00 30 49 09 79 89 00 08 43 2e 49 49 79 49 00

08 43 2c 49 89 79 08 43 2b 49 08 70 2b 48 00 78 00 28 05 d1 29 48 00 78 40 1c 28 49 08 70 02 e0

01 20 27 49 08 70 27 48 00 78 00 28 22 d1 01 20 25 49 88 70 00 20 c8 70 08 71 48 71 88 71 c8 71

08 72 48 72 1c 48 00 78 04 28 02 d0 06 28 0c d1 07 e0 1e 48 00 78 1c 49 c8 70 01 20 c8 71 48 72

07 e0 01 20 18 49 c8 70 03 e0 01 20 18 49 08 70 72 e7 00 bf 14 49 13 4a 12 78 88 5c 01 f0 3c fe

10 48 00 78 40 1c 0f 49 08 70 08 46 00 78 09 28 0b dd 04 20 00 f0 74 f9 01 f0 18 fe 00 20 09 49

08 70 03 49 08 70 0b 49 08 70 00 bf 54 e7 00 00 21 01 00 20 19 01 00 20 23 01 00 20 15 01 00 20

12 01 00 20 22 01 00 20 84 01 00 20 17 01 00 20 13 01 00 20 24 01 00 20 28 48 00 78 40 02 28 49

09 78 49 00 08 43 27 49 08 80 24 48 00 78 40 06 c0 0f 25 49 48 71 21 48 00 78 80 06 c0 0f c8 72

1e 48 00 78 c0 06 c0 0f 08 72 1c 48 00 78 00 07 c0 0f 08 74 19 48 00 78 40 07 c0 0f 88 73 17 48

00 78 80 07 c0 0f 48 73 14 48 00 78 c0 07 c0 0f c8 71 13 48 00 78 40 06 c0 0f c8 70 10 48 00 78

80 06 c0 0f 08 73 0e 48 00 78 c0 06 c0 0f 08 71 0b 48 00 78 00 07 c0 0f 88 72 09 48 00 78 40 07

c0 0f 48 72 06 48 00 78 80 07 c0 0f c8 73 04 48 00 78 c0 07 c0 0f 88 71 70 47 00 00 35 01 00 20

36 01 00 20 2e 01 00 20 84 01 00 20 03 48 00 88 03 49 08 40 01 49 08 80 70 47 00 00 2c 01 00 20

fe fe 00 00 70 b5 04 46 01 20 00 03 84 42 06 d1 01 f0 9a f8 20 46 01 f0 b7 f9 05 46 22 e0 01 20

40 03 84 42 06 d1 01 f0 8f f8 20 46 01 f0 ac f9 05 46 17 e0 07 20 00 03 84 42 0c d1 01 f0 84 f8

20 46 01 f0 a1 f9 05 46 4b 21 c9 00 28 46 02 f0 45 f8 05 46 06 e0 20 46 01 f0 76 f8 20 46 01 f0

93 f9 05 46 28 46 70 bd 70 47 70 47 38 b5 04 46 6a 46 02 21 20 46 ff f7 a1 f9 69 46 48 78 00 02

09 78 08 43 05 b2 06 2c 02 d1 02 48 28 18 05 b2 28 46 38 bd 55 f5 ff ff 7c b5 11 a0 00 68 01 90

01 aa 02 21 3e 20 ff f7 94 f9 00 f0 94 f8 6a 46 04 21 40 20 ff f7 82 f9 68 46 40 78 01 02 68 46

00 78 01 43 0c 46 68 46 c0 78 00 02 69 46 89 78 08 43 05 46 ac 42 01 da 28 46 7c bd 20 46 fc e7

71 00 00 00 10 b5 01 20 00 03 ff f7 8b ff 04 46 12 49 ff f7 2f f8 10 d3 01 20 40 03 ff f7 82 ff

04 46 0e 49 ff f7 26 f8 07 d3 00 20 ff f7 7a ff 04 46 0a 49 ff f7 1e f8 05 d2 09 48 00 78 40 1c

07 49 08 70 02 e0 00 20 05 49 08 70 04 48 00 78 09 28 01 dd 01 20 10 bd 00 20 fc e7 00 00 53 43

5d 01 00 20 10 b5 04 46 00 2c 02 d0 00 20 00 f0 4f ff 01 22 11 46 80 20 01 f0 98 fa 00 2c 02 d0

01 20 00 f0 45 ff 10 bd 10 b5 04 46 00 2c 02 d0 00 20 00 f0 3d ff 01 22 11 46 40 20 01 f0 86 fa

00 2c 02 d0 01 20 00 f0 33 ff 10 bd 10 b5 00 24 00 bf 03 e0 00 f0 05 f8 60 1c c4 b2 19 2c f9 db

10 bd 10 b5 00 f0 17 f8 00 f0 15 f8 00 f0 13 f8 00 f0 11 f8 10 bd 10 b5 00 24 0a 24 03 e0 00 f0

0a f8 60 1e c4 b2 00 2c f9 dc 10 bd 10 b5 03 20 ff f7 b8 f8 10 bd 10 b5 22 20 ff f7 b3 f8 10 bd

70 b5 04 46 25 46 03 e0 ff f7 f5 ff 68 1e c5 b2 00 2d f9 dc 70 bd 70 47 8a b0 00 20 09 90 08 90

00 26 00 27 07 90 06 90 05 90 04 90 03 90 02 90 01 90 e1 20 40 01 fe 49 08 80 c0 10 fd 49 08 80

fd 48 fe 49 08 60 fe 49 08 60 0a 20 fd 49 08 70 83 e3 01 f0 91 ff fc 48 00 68 00 28 43 d1 58 20

01 f0 42 fd 05 46 f9 48 00 78 00 28 36 d1 1f 2d 05 d1 00 f0 e5 fb 01 20 f4 49 08 70 21 e0 00 2d

03 d1 71 20 01 f0 d0 fc 1b e0 0c 2d 06 dd 10 2d 04 da a8 00 28 18 c0 b2 00 90 12 e0 01 2d 07 dd

0c 2d 05 da 68 1c 81 00 40 18 c0 b2 00 90 08 e0 0c 2d 02 d1 3f 20 00 90 03 e0 01 2d 01 d1 0f 20

00 90 e3 48 00 78 00 28 08 d1 e2 48 02 78 e2 48 00 78 00 99 01 f0 7c fc dd 49 08 70 7d 20 00 01

d9 49 08 60 36 e3 d5 48 00 68 00 28 70 d1 0c 20 ff f7 cc fe 07 46 d9 48 87 42 05 dd ff f7 6b ff

0c 20 ff f7 c3 fe 07 46 3c 46 00 bf cf 48 00 78 00 28 72 d1 d2 48 84 42 0a da 07 98 40 1c c0 b2

07 90 07 98 02 28 05 dd 77 20 01 f0 7d fc 01 e0 00 20 07 90 c9 48 87 42 02 dd 75 20 01 f0 74 fc

c8 48 84 42 0a dd 03 98 40 1c c0 b2 03 90 03 98 02 28 05 dd 74 20 01 f0 67 fc 01 e0 00 20 03 90

c1 48 00 78 01 28 53 d1 c0 48 00 68 c0 49 88 42 02 dd 05 20 06 90 25 e0 bc 48 00 68 bc 49 49 1f

88 42 02 dd 04 20 06 90 1c e0 b8 48 00 68 b8 49 14 39 88 42 02 dd 03 20 06 90 13 e0 b3 48 00 68

b3 49 1e 39 88 42 02 dd 02 20 06 90 0a e0 af 48 00 68 af 49 28 39 88 42 02 dd 01 20 06 90 01 e0

00 20 06 90 ab 48 84 42 03 dd 00 20 05 90 d2 e0 17 e1 a8 48 64 38 84 42 02 dd 01 20 05 90 ca e0

a4 48 c8 38 84 42 02 dd 02 20 05 90 c3 e0 a2 48 84 42 03 dd 03 20 05 90 bd e0 f9 e0 9e 48 64 38

84 42 02 dd 04 20 05 90 b5 e0 05 20 05 90 b2 e0 95 48 00 78 02 28 52 d1 94 48 00 68 94 49 88 42

02 dd 05 20 06 90 25 e0 90 48 00 68 90 49 49 1f 88 42 02 dd 04 20 06 90 1c e0 8c 48 00 68 8c 49

14 39 88 42 02 dd 03 20 06 90 13 e0 87 48 00 68 87 49 1e 39 88 42 02 dd 02 20 06 90 0a e0 83 48

00 68 83 49 28 39 88 42 02 dd 01 20 06 90 01 e0 00 20 06 90 7f 48 c8 30 84 42 02 dd 00 20 05 90

79 e0 7c 48 64 30 84 42 02 dd 01 20 05 90 72 e0 78 48 84 42 02 dd 02 20 05 90 6c e0 75 48 64 38

84 42 02 dd 03 20 05 90 65 e0 73 48 64 30 84 42 02 dd 04 20 05 90 5e e0 05 20 05 90 5b e0 6a 48

00 78 03 28 53 d1 69 48 00 68 6c 49 88 42 02 dd 05 20 06 90 25 e0 65 48 00 68 68 49 3c 39 88 42

02 dd 04 20 06 90 1c e0 60 48 00 68 63 49 64 39 88 42 02 dd 03 20 06 90 13 e0 5c 48 00 68 7d 21

49 01 88 42 02 dd 02 20 06 90 0a e0 57 48 00 68 5a 49 a0 39 88 42 02 dd 01 20 06 90 01 e0 00 20

06 90 54 48 64 38 84 42 02 dd 00 20 05 90 22 e0 19 20 40 01 84 42 02 dd 01 20 05 90 1b e0 4b 20

c0 00 84 42 02 dd 02 20 05 90 14 e0 ff 20 c3 30 84 42 02 dd 03 20 05 90 0d e0 ff 20 2d 30 84 42

02 dd 04 20 05 90 06 e0 05 20 05 90 03 e0 00 20 06 90 05 20 05 90 05 99 06 98 40 18 05 28 0a dd

02 98 40 1c c0 b2 02 90 02 98 05 28 05 dd 5a 20 01 f0 4a fb 01 e0 00 20 02 90 39 48 00 88 84 42

11 dd 37 48 00 88 37 49 88 42 0c dd 36 48 00 78 00 28 05 d0 34 48 00 78 40 1e 33 49 08 70 02 e0

55 20 01 f0 31 fb 29 48 00 68 29 49 24 39 88 42 0f dd 2e 48 84 42 0c dd 1a 48 00 78 40 1e 19 49

08 70 08 46 00 78 00 28 06 d1 55 20 01 f0 1c fb 02 e0 0a 20 13 49 08 70 7d 20 c0 00 0f 49 08 60

a8 e1 23 48 00 68 00 28 7e d1 ff f7 55 fd 06 46 20 48 86 42 03 dc 7d 20 00 01 86 42 43 da ff f7

da fd ff f7 49 fd 06 46 1a 48 86 42 38 dc 33 e0 3c 01 00 20 3e 01 00 20 20 4e 00 00 44 01 00 20

50 01 00 20 65 01 00 20 48 01 00 20 37 01 00 20 58 01 00 20 33 01 00 20 5a 01 00 20 10 27 00 00

30 f8 ff ff 34 21 00 00 0b 01 00 20 0c 01 00 20 8a 11 00 00 1a 04 00 00 ee 02 00 00 22 10 00 00

62 01 00 20 fc 08 00 00 64 01 00 20 e4 0c 00 00 40 01 00 20 88 13 00 00 7d 20 00 01 86 42 02 da

76 20 01 f0 c1 fa ad 48 06 60 ad 48 00 78 00 28 7e d1 ac 48 00 88 00 28 07 d1 ab 48 00 78 28 28

1e dd 28 20 a8 49 08 70 1a e0 a6 48 00 88 ff 21 e1 31 88 42 07 da a4 48 00 78 32 28 10 dd 32 20

a1 49 08 70 0c e0 9f 48 00 88 2d 21 09 01 88 42 06 da 9d 48 00 78 3c 28 02 dd 3c 20 9a 49 08 70

9a 48 00 78 00 28 00 e0 a0 e0 19 d1 93 48 00 68 97 49 88 42 07 dd 94 48 00 78 49 28 10 dd 49 20

91 49 08 70 0c e0 8d 48 00 68 91 49 fa 39 88 42 06 dd 8d 48 00 78 49 28 02 dd 49 20 8a 49 08 70

86 48 00 68 8a 49 96 39 88 42 07 dd 86 48 00 78 49 28 1e dd 49 20 84 49 08 70 1a e0 7f 48 00 68

21 21 c9 01 88 42 07 dd 7f 48 00 78 49 28 10 dd 49 20 7d 49 08 70 0c e0 78 48 00 68 7c 49 e6 39

88 42 06 dd 78 48 00 78 49 28 02 dd 49 20 76 49 08 70 78 48 00 78 00 28 09 d1 77 48 02 78 77 48

01 78 71 48 00 78 01 f0 13 fa 72 49 08 70 00 e0 44 e0 73 48 00 78 02 28 08 d1 68 48 00 68 6c 49

14 39 88 42 02 dd 5a 20 01 f0 2e fa 6d 48 00 78 01 28 1a d1 61 48 00 68 6b 49 88 42 02 dd 5a 20

01 f0 22 fa 5d 48 00 68 67 49 0a 39 88 42 0a dd 08 98 40 1c c0 b2 08 90 08 98 05 28 05 dd 5a 20

01 f0 12 fa 01 e0 00 20 08 90 54 48 00 68 58 49 32 31 88 42 02 dd 5a 20 01 f0 06 fa 4f 48 00 68

53 49 28 31 88 42 0a dd 09 98 40 1c c0 b2 09 90 09 98 05 28 05 dd 5a 20 01 f0 f6 f9 01 e0 00 20

09 90 ff 20 f5 30 51 49 08 60 83 e0 50 48 00 68 00 28 2a d1 06 20 ff f7 19 fc 04 46 40 48 00 78

00 28 1d d1 00 2c 0e dd 46 48 00 78 00 28 03 d1 ff 20 f5 30 84 42 06 dc 42 48 00 78 01 28 0d d1

44 48 84 42 0a dd 04 98 40 1c c0 b2 04 90 04 98 02 28 05 dd 5c 20 01 f0 c7 f9 01 e0 00 20 04 90

ff 20 f5 30 3a 49 08 60 54 e0 3b 48 00 68 00 28 1e d1 2b 48 00 78 00 28 0e d1 ff f7 23 fc 00 28

05 d0 00 20 00 f0 bc f8 01 20 25 49 08 70 19 20 40 01 31 49 08 60 3d e0 01 98 00 28 04 d1 5d 20

01 f0 02 fa 01 20 01 90 2c 48 2b 49 08 60 31 e0 2b 48 00 78 00 28 2d d1 2a 48 00 88 00 28 06 d1

17 48 00 78 00 28 02 d1 5a 20 01 f0 8d f9 26 48 00 78 00 28 02 d0 59 20 01 f0 86 f9 23 48 00 78

00 28 02 d0 73 20 01 f0 7f f9 21 48 00 78 00 28 02 d0 72 20 01 f0 78 f9 1e 48 00 78 00 28 03 d1

1d 48 00 78 01 28 02 dd 54 20 01 f0 6d f9 14 20 13 49 08 70 2f 20 ff f7 53 fc 7a e4 0c 01 00 20

37 01 00 20 3e 01 00 20 5a 01 00 20 5b 01 00 20 62 11 00 00 58 01 00 20 33 01 00 20 32 01 00 20

66 01 00 20 0a 01 00 20 2c 10 00 00 40 01 00 20 50 01 00 20 26 02 00 00 54 01 00 20 10 27 00 00

4c 01 00 20 3c 01 00 20 18 01 00 20 13 01 00 20 12 01 00 20 10 01 00 20 61 01 00 20 30 e0 01 f0

db fb 18 48 00 68 00 28 0a d1 58 20 01 f0 8c f9 00 28 01 d1 01 f0 38 f9 13 48 12 49 08 60 1f e0

12 48 00 78 00 28 1b d1 11 48 00 78 00 28 02 d0 73 20 01 f0 19 f9 0f 48 00 78 00 28 02 d0 72 20

01 f0 12 f9 0c 48 00 78 00 28 03 d1 0b 48 00 78 01 28 02 dd 54 20 01 f0 07 f9 14 20 03 49 08 70

cd e7 00 00 48 01 00 20 70 17 00 00 4c 01 00 20 13 01 00 20 12 01 00 20 10 01 00 20 61 01 00 20

00 28 03 d0 05 49 06 4a 51 60 03 e0 01 21 09 04 03 4a 51 60 03 49 08 70 70 47 00 00 01 00 01 00

00 00 05 50 67 01 00 20 70 47 00 00 01 49 48 7c 70 47 00 00 40 00 03 50 10 b5 20 20 00 f0 42 fe

04 46 20 46 10 bd 00 00 03 48 00 78 00 28 01 d1 01 20 70 47 00 20 fc e7 67 01 00 20 10 b5 03 20

40 03 00 f0 75 fd 01 49 08 60 10 bd 68 01 00 20 10 b5 01 22 00 21 08 20 00 f0 cc fd ff f7 9b fb

08 20 00 f0 1f fe 04 46 00 2c 06 d0 01 20 05 49 08 70 64 20 04 49 08 80 02 e0 00 20 01 49 08 70

10 bd 00 00 6c 01 00 20 6e 01 00 20 10 b5 00 20 00 f0 b0 ff c4 b2 64 06 64 0e 20 46 10 bd 10 b5

00 21 08 46 00 f0 1a fe 10 bd 00 00 08 b5 01 21 68 46 01 70 00 21 41 70 02 21 81 70 01 21 c1 70

fe f7 74 fc 01 20 40 07 fd 49 48 60 fd 48 fe 49 88 60 00 f0 87 fa 01 f0 e3 f9 01 f0 17 fb ff f7

b7 ff fa 48 00 78 01 28 05 d1 03 e0 01 f0 14 fb 00 f0 88 fa fa e7 01 f0 0f fb 00 f0 74 fa ff f7

ce ff 00 20 ff f7 10 fb 01 20 00 f0 51 fa 53 20 01 f0 42 f9 05 46 2d 07 2d 0f 00 2d 01 d1 0a 24

16 e0 01 2d 01 d1 3c 24 12 e0 02 2d 01 d1 82 24 0e e0 03 2d 01 d1 aa 24 0a e0 04 2d 02 d1 ff 24

69 34 05 e0 05 2d 02 d1 ff 24 f5 34 00 e0 0a 24 32 2c 0b db 78 2c 09 da dd 48 de 49 08 60 04 20

dd 49 08 70 02 20 dd 49 08 70 4c e0 78 2c 0b db a0 2c 09 da da 48 d7 49 08 60 06 20 d6 49 08 70

01 20 d8 49 08 70 3e e0 a0 2c 0d db ff 20 5f 30 84 42 09 da d4 48 cf 49 08 60 0a 20 ce 49 08 70

01 20 d0 49 08 70 2e e0 ff 20 5f 30 84 42 0d db ff 20 af 30 84 42 09 da cc 48 c6 49 08 60 0a 20

c5 49 08 70 02 20 c7 49 08 70 1c e0 ff 20 af 30 84 42 0f db c6 48 84 42 0c da c6 48 bd 49 08 60

02 20 bd 49 08 70 01 20 c3 49 08 70 03 20 bd 49 08 70 08 e0 c1 48 b7 49 08 60 04 20 b6 49 08 70

02 20 b6 49 08 70 b4 49 08 78 c1 0f 09 18 49 10 bb 4a 11 70 10 46 00 78 08 21 08 40 c0 10 b9 49

08 70 10 46 00 78 04 21 08 40 80 10 b6 49 08 70 10 46 00 78 02 21 08 40 40 10 b4 49 08 70 10 46

00 78 c0 07 c0 0f b2 49 08 70 00 f0 e7 ff 00 f0 fc ff 00 f0 4b ff 00 f0 19 ff 00 20 ff f7 52 fa

00 bf ff f7 a8 fa 01 f0 57 fa 01 f0 06 f8 00 28 f7 d0 11 e0 01 f0 50 fa a6 48 00 78 00 28 01 d0

00 f0 b2 ff a4 48 00 78 01 28 00 d1 05 e0 a3 48 00 78 00 28 00 d1 00 e0 ec e7 00 bf 52 20 00 f0

f3 ff 05 46 01 20 9e 49 08 70 00 2d 01 d1 00 f0 9b ff 01 f0 31 fa 16 e0 01 f0 2e fa 95 48 00 78

00 28 02 d0 54 20 00 f0 7f ff 93 48 00 78 01 28 04 d1 94 48 00 78 01 28 00 d1 05 e0 8f 48 00 78

00 28 00 d1 00 e0 e7 e7 00 bf 01 20 8e 49 08 70 ff f7 9a f9 8d 48 00 78 00 f0 c6 ff 05 46 02 2d

01 d0 00 f0 71 ff 01 f0 07 fa 01 f0 05 fa 87 48 00 78 00 28 03 d0 ff f7 9f f9 85 49 08 60 ff f7

15 fa 82 48 00 78 00 28 03 d0 2c 20 ff f7 7e f9 c6 b2 55 2e 27 dd ff 20 5f 30 84 42 05 db 14 20

7c 49 08 70 7c 49 08 70 8e e0 a0 2c 05 db 14 20 78 49 08 70 78 49 08 70 86 e0 78 2c 05 db 0f 20

74 49 08 70 74 49 08 70 7e e0 32 2c 05 db 0a 20 70 49 08 70 70 49 08 70 76 e0 0a 20 6d 49 08 70

6d 49 08 70 70 e0 4b 2e 27 dd ff 20 5f 30 84 42 05 db 1e 20 67 49 08 70 67 49 08 70 64 e0 a0 2c

05 db 1e 20 63 49 08 70 63 49 08 70 5c e0 78 2c 05 db 19 20 5f 49 08 70 5f 49 08 70 54 e0 32 2c

05 db 0f 20 5b 49 08 70 5b 49 08 70 4c e0 0a 20 58 49 08 70 58 49 08 70 46 e0 32 2e 27 dd ff 20

5f 30 84 42 05 db 2d 20 52 49 08 70 52 49 08 70 3a e0 a0 2c 05 db 28 20 4e 49 08 70 4e 49 08 70

32 e0 78 2c 05 db 28 20 4a 49 08 70 4a 49 08 70 2a e0 32 2c 05 db 14 20 46 49 08 70 46 49 08 70

22 e0 0e 20 43 49 08 70 43 49 08 70 1c e0 a0 2c 05 db 49 20 3f 49 08 70 3f 49 08 70 14 e0 78 2c

05 db 32 20 3b 49 08 70 3b 49 08 70 0c e0 32 2c 05 db 19 20 37 49 08 70 37 49 08 70 04 e0 14 20

34 49 08 70 34 49 08 70 23 48 00 78 01 28 04 d1 0d 20 30 49 08 70 30 49 08 70 ff f7 67 f9 ff f7

dd fd 58 20 00 f0 00 ff 01 20 2c 49 08 70 23 48 00 78 00 28 01 d1 ff f7 61 fd 0c e0 01 f0 3c f9

1c 48 00 78 00 28 03 d1 1d 48 00 78 01 28 02 dd 54 20 00 f0 89 fe ff f7 b7 fd 01 28 ee d0 3f e0

00 00 02 50 07 00 47 00 00 00 05 50 6c 01 00 20 3c 37 00 21 00 01 00 20 04 01 00 20 66 01 00 20

58 37 00 21 0b 01 00 20 82 37 00 21 c8 37 00 21 12 02 00 00 0e 38 00 21 0a 01 00 20 20 37 00 21

05 01 00 20 06 01 00 20 07 01 00 20 08 01 00 20 09 01 00 20 10 01 00 20 30 01 00 20 5f 01 00 20

61 01 00 20 2a 01 00 20 31 01 00 20 26 01 00 20 0c 01 00 20 59 01 00 20 5a 01 00 20 17 01 00 20

ff f7 3a f9 70 b5 02 46 00 29 0a d1 15 4d 16 4e b5 60 ff 25 2d 04 15 43 14 4e 35 43 12 4e 35 60

13 e0 01 29 11 d1 d5 06 ed 0e 60 26 16 40 76 00 35 43 2a 46 0b 4d 6d 1c 0b 4e b5 60 ff 25 2d 04

15 43 0a 4e 35 43 08 4e 35 60 07 4d ac 68 01 e0 05 4d ac 68 e5 05 ed 0f 00 2d f9 d0 02 4d 6b 68

d8 b2 70 bd 01 00 0f 00 00 00 03 40 00 80 00 80 00 28 09 d0 0a 49 09 78 00 29 05 d1 00 bf 62 b6

00 bf 07 49 08 70 0a e0 00 28 08 d1 04 49 09 78 00 29 04 d0 00 bf 72 b6 00 bf 01 49 08 70 70 47

72 01 00 20 70 47 10 b5 ff f7 0e fd 00 f0 a0 fd 00 f0 75 fd 00 f0 7a fd 00 f0 48 fd ff f7 15 f8

10 bd 00 00 fe b5 05 20 00 03 00 f0 91 fa 05 46 64 21 69 43 08 46 35 49 fd f7 a6 fd 34 49 40 18

87 b2 03 20 40 03 00 f0 83 fa 05 46 64 21 69 43 08 46 2e 49 fd f7 98 fd 2d 49 40 18 86 b2 01 20

00 03 fe f7 bf ff 00 90 fe f7 1a f8 00 b2 01 90 00 20 fe f7 b7 ff 00 90 fe f7 12 f8 00 b2 02 90

38 04 30 43 23 49 08 60 02 98 00 04 01 99 08 43 20 49 48 60 08 46 84 68 20 0c 1f 49 88 42 07 d1

1e 48 00 78 00 28 0a d1 01 20 ff f7 a9 fc 06 e0 1a 48 00 78 01 28 02 d1 00 20 ff f7 a1 fc ff f7

55 f8 17 48 00 88 00 28 04 dd 15 48 00 88 40 1e 13 49 08 80 12 48 00 88 00 28 15 d1 0d 48 84 68

a0 b2 00 28 03 d0 0d 48 00 78 00 28 07 d1 0d 48 20 43 08 49 88 60 64 20 09 49 08 80 04 e0 00 20

ff f7 7e fc 00 f0 80 fd fe bd 00 00 22 02 00 00 70 17 00 00 c0 00 02 50 a5 a5 00 00 67 01 00 20

6e 01 00 20 ff ff 00 00 f1 b5 82 b0 02 98 01 90 05 21 09 03 01 98 88 42 2b d1 01 20 80 05 85 49

08 60 01 21 13 20 ff f7 0d ff 07 46 01 21 12 20 ff f7 08 ff 06 46 38 02 30 43 07 46 38 46 fd f7

98 ff 47 21 09 06 00 90 fd f7 b8 fd 7a 49 08 60 01 21 11 20 ff f7 f6 fe 04 46 01 21 10 20 ff f7

f1 fe 05 46 21 02 29 43 0c 46 20 b2 73 49 08 80 de e0 03 21 49 03 01 98 88 42 2b d1 01 20 40 05

6c 49 08 60 01 21 17 20 ff f7 dc fe 07 46 01 21 16 20 ff f7 d7 fe 06 46 38 02 30 43 07 46 38 46

fd f7 67 ff 47 21 09 06 00 90 fd f7 87 fd 62 49 08 60 01 21 15 20 ff f7 c5 fe 04 46 01 21 14 20

ff f7 c0 fe 05 46 21 02 29 43 0c 46 20 b2 5b 49 08 80 ad e0 07 21 09 03 01 98 88 42 4e d1 01 21

1b 20 ff f7 af fe 07 46 01 21 1a 20 ff f7 aa fe 06 46 38 02 30 43 07 46 38 46 fd f7 3a ff 47 21

09 06 00 90 fd f7 5a fd 4b 49 08 60 01 21 19 20 ff f7 98 fe 04 46 01 21 18 20 ff f7 93 fe 05 46

20 02 28 43 04 46 20 b2 44 49 08 80 01 21 1f 20 ff f7 88 fe 07 46 01 21 1e 20 ff f7 83 fe 06 46

38 02 30 43 07 46 38 46 fd f7 13 ff 47 21 09 06 00 90 fd f7 33 fd 3a 49 08 60 01 21 1d 20 ff f7

71 fe 04 46 01 21 1c 20 ff f7 6c fe 05 46 20 02 28 43 04 46 20 b2 33 49 08 80 59 e0 01 21 c9 03

01 98 88 42 27 d1 01 21 23 20 ff f7 5b fe 07 46 01 21 22 20 ff f7 56 fe 06 46 38 02 30 43 07 46

38 46 fd f7 e6 fe 47 21 09 06 00 90 fd f7 06 fd 21 49 08 60 01 21 21 20 ff f7 44 fe 04 46 01 21

20 20 ff f7 3f fe 05 46 21 02 29 43 0c 46 20 b2 1a 49 08 80 2c e0 01 21 0f 20 ff f7 33 fe 07 46

01 21 0e 20 ff f7 2e fe 06 46 38 02 30 43 07 46 38 46 fd f7 be fe 47 21 09 06 00 90 fd f7 de fc

0d 49 08 60 01 21 0d 20 ff f7 1c fe 04 46 01 21 0c 20 ff f7 17 fe 05 46 21 02 29 43 0c 46 20 b2

06 49 08 80 7d 20 c0 00 84 42 01 dd 0b 20 08 80 fe bd 00 00 00 00 06 50 74 01 00 20 7c 01 00 20

78 01 00 20 7e 01 00 20 f1 b5 8c b0 05 20 09 90 0c 9c 6a 48 6a 49 08 60 0f 20 00 07 20 43 08 60

68 48 80 89 c0 05 c0 0f 01 21 48 40 05 90 65 48 80 89 40 04 c0 0f 04 90 0b e0 62 48 80 89 c0 05

c0 0f 01 21 48 40 05 90 5e 48 80 89 40 04 c0 0f 04 90 05 98 00 28 f0 d0 04 98 00 28 ed d0 20 46

00 f0 e8 f8 0b 90 00 27 00 20 0a 90 19 e0 56 48 53 49 08 60 00 bf 52 48 00 68 02 21 08 40 00 28

f9 d1 4f 48 80 68 01 b2 0a 98 40 00 06 aa 11 52 0a 98 40 00 06 a9 08 5e c7 19 0a 98 40 1c c0 b2

0a 90 09 99 0a 98 88 42 e1 db 05 21 38 46 fd f7 bb fb 07 46 3f b2 07 20 00 03 84 42 1d d1 43 48

87 42 1a dd 42 49 00 20 08 5e fd f7 27 fe 3a b2 02 90 0b 99 50 1a fd f7 21 fe 00 90 3d 48 01 68

00 98 fd f7 0e fc 01 90 02 99 fd f7 b1 fb 03 90 fd f7 3f fe 05 46 0e 46 18 e0 37 49 00 20 08 5e

fd f7 0c fe 02 90 0b 99 78 1a fd f7 07 fe 00 90 32 48 01 68 00 98 fd f7 f4 fb 01 90 02 99 fd f7

97 fb 03 90 fd f7 25 fe 05 46 0e 46 05 20 00 03 84 42 07 d0 03 20 40 03 84 42 03 d0 07 20 00 03

84 42 14 d1 00 22 26 4b 28 46 31 46 fd f7 06 fd 00 22 24 4b 01 91 00 90 fd f7 68 fd 00 22 20 4b

03 91 02 90 fd f7 48 fc 05 46 0e 46 20 e0 01 20 c0 03 84 42 0e d1 00 22 1b 4b 28 46 31 46 fd f7

ed fc 00 22 17 4b 03 91 02 90 fd f7 4f fd 05 46 0e 46 0d e0 00 22 15 4b 28 46 31 46 fd f7 de fc

00 22 10 4b 03 91 02 90 fd f7 40 fd 05 46 0e 46 28 46 31 46 fd f7 f1 fd 0d b0 f0 bd 01 00 01 00

00 00 06 50 00 00 05 50 02 00 02 00 77 37 00 00 7e 01 00 20 78 01 00 20 7c 01 00 20 74 01 00 20

00 70 a7 40 00 00 e0 40 00 00 59 40 00 c0 a2 40 10 b5 01 46 0b 46 0c 48 0c 4c 20 60 80 01 20 60

40 10 20 60 0f 20 00 07 18 43 20 60 00 22 08 48 20 60 00 bf 05 48 00 68 02 24 20 40 00 28 f9 d1

02 48 82 68 10 b2 10 bd 01 00 01 00 00 00 06 50 02 00 02 00 01 46 05 22 12 03 91 42 07 d0 03 22

52 03 91 42 03 d0 07 22 12 03 91 42 03 d1 0c 4a 0c 4b 1a 60 02 e0 0c 4a 0a 4b 1a 60 0b 4a 09 4b

1a 60 00 bf 07 4a 12 68 02 23 1a 40 00 2a f9 d1 04 4a 92 68 10 b2 03 22 52 06 02 4b 1a 60 70 47

00 04 00 04 00 00 06 50 00 02 00 02 02 00 02 00 01 49 08 73 70 47 00 00 40 00 03 50 04 49 09 78

09 02 01 43 02 4a 12 78 11 43 08 46 70 47 00 00 40 00 03 50 70 b5 0b 46 14 46 00 2b 05 d0 11 4d

2d 79 05 43 0f 4e 35 71 1b e0 05 04 05 43 0e 4e 35 60 0c 4d 2d 79 85 43 0a 4e 35 71 00 21 0e e0

01 25 8d 40 05 40 00 2d 08 d0 4a 00 25 46 95 40 03 26 96 40 36 04 35 43 03 4e 75 60 49 1c 07 29

ee db 70 bd 00 00 03 50 40 00 02 50 10 b5 14 4b 1b 7d 83 43 12 4c 23 75 00 29 04 d0 23 46 1b 7e

03 43 23 76 04 e0 0e 4b 1b 7e 83 43 0c 4c 23 76 00 2a 05 d0 0a 4b 1b 7f 03 43 09 4c 23 77 04 e0

07 4b 1b 7f 83 43 06 4c 23 77 ff 23 04 4c 20 34 23 72 03 4b 1b 7c 03 43 01 4c 23 74 10 bd 00 00

20 00 03 50 01 46 04 48 00 7c 08 40 00 28 01 d0 01 20 70 47 00 20 fc e7 40 00 03 50 00 29 05 d0

05 4a 12 78 02 43 04 4b 1a 70 04 e0 02 4a 12 78 82 43 01 4b 1a 70 70 47 00 00 03 50 f8 b5 06 46

0c 46 19 48 19 49 08 63 00 12 48 63 0a 20 fd f7 02 fe 01 20 00 06 15 49 08 63 00 12 48 63 0a 20

fd f7 f9 fd 07 27 3f 06 00 2e 11 d1 03 25 2d 02 00 2c 03 d1 0e 48 0f 49 48 60 0b e0 01 2c 03 d1

0d 48 0c 49 48 60 05 e0 0b 48 0a 49 48 60 01 e0 ff 25 01 35 01 20 c0 05 06 49 08 60 38 46 28 43

06 49 48 60 f8 bd 00 00 00 01 00 01 00 00 01 50 08 00 08 00 00 00 02 40 01 00 01 00 00 00 02 50

f8 b5 04 46 0d 46 16 46 1f 46 01 20 3b 46 32 46 29 46 00 90 20 46 00 f0 01 f8 f8 bd ff b5 81 b0

0d 46 16 46 1f 46 3c 46 1c e0 20 2c 13 dd 20 23 32 46 29 46 01 98 00 f0 17 f8 00 28 02 d0 01 20

05 b0 f0 bd 20 36 20 3c 0a 98 00 28 0a d0 28 46 20 30 c5 b2 06 e0 23 46 32 46 29 46 01 98 00 f0

03 f8 ed e7 e1 e7 00 00 ff b5 0d 46 00 98 40 06 06 0e 20 2b 02 dd 01 20 04 b0 f0 bd 28 02 30 43

28 4f 38 60 28 48 29 4f 38 60 02 20 38 61 00 bf 26 48 00 6a 02 28 fb d1 01 20 30 43 21 4f 38 60

21 48 22 4f 38 60 01 20 38 61 00 bf 1f 48 00 6a 01 28 fb d1 1e 48 1d 4f 38 60 38 46 43 61 00 bf

1a 48 00 6a 98 42 fb d1 19 48 14 38 17 4f 38 60 00 24 15 e0 17 48 a7 10 bf 00 c1 59 11 70 52 1c

ff 20 00 02 08 40 00 0a 10 70 52 1c ff 20 00 04 08 40 00 0c 10 70 52 1c 08 0e 10 70 52 1c 24 1d

9c 42 e7 db 00 bf 09 48 c0 69 20 27 38 40 20 28 f9 d1 00 20 c0 43 05 4f f8 61 07 48 38 60 00 20

aa e7 00 00 00 01 02 40 09 00 ff 00 00 00 02 40 25 00 7f 00 00 02 02 40 00 00 ff 07 f8 b5 04 46

0d 46 16 46 1f 46 01 20 3b 46 32 46 29 46 00 90 20 46 00 f0 01 f8 f8 bd ff b5 81 b0 0d 46 16 46

1f 46 3c 46 1c e0 1e 2c 13 dd 1e 23 32 46 29 46 01 98 00 f0 17 f8 00 28 02 d0 01 20 05 b0 f0 bd

1e 36 1e 3c 0a 98 00 28 0a d0 28 46 1e 30 c5 b2 06 e0 23 46 32 46 29 46 01 98 00 f0 03 f8 ed e7

e1 e7 00 00 ff b5 81 b0 0d 46 01 98 40 06 00 0e 00 90 00 26 1c 46 1e 2b 01 dc 00 2b 02 d1 01 20

05 b0 f0 bd 28 02 00 9f 38 43 01 46 10 78 52 1c 00 04 01 43 01 2b 03 d0 10 78 52 1c 00 06 01 43

24 48 01 60 02 2c 27 dd a4 1e 14 e0 24 1f 00 21 11 78 52 1c 10 78 52 1c 00 02 01 43 10 78 52 1c

00 04 01 43 10 78 52 1c 00 06 01 43 19 48 00 1d b7 00 c1 51 76 1c 04 2c e8 dc 10 78 57 78 3f 02

38 43 97 78 3f 04 38 43 d7 78 3f 06 38 43 01 46 10 48 00 1d b7 00 c1 51 0f 48 10 4f 38 60 98 1c

38 61 00 bf 0d 48 00 6a 9f 1c b8 42 fa d1 0a 48 08 30 0a 4f 38 60 00 bf 08 48 c0 69 20 27 38 40

20 28 f9 d1 00 20 c0 43 04 4f f8 61 04 48 38 60 00 20 a5 e7 00 01 02 40 09 00 ff 00 00 00 02 40

00 00 ff 01 42 01 02 4b d1 18 01 22 8a 61 70 47 00 00 04 50 01 46 48 01 01 4b c2 18 90 68 70 47

00 00 04 50 10 b5 01 46 01 20 4b 01 02 4c 1a 19 13 69 18 40 10 bd 00 00 00 00 04 50 30 b5 03 46

5c 01 05 4d 60 19 01 60 00 2a 02 d0 04 24 04 61 01 e0 00 24 04 61 30 bd 00 00 04 50 42 01 03 4b

d1 18 0a 69 01 23 1a 43 0a 61 70 47 00 00 04 50 76 20 01 49 c8 60 70 47 00 00 01 40 0a 4a 50 60

00 22 09 4b 1a 60 00 29 05 d0 1a 46 12 68 02 23 1a 43 05 4b 1a 60 04 4a 12 68 01 23 1a 43 02 4b

1a 60 76 22 da 60 70 47 00 00 01 40 10 b5 07 48 07 49 88 60 00 22 11 46 80 20 ff f7 ab fd 00 22

11 46 01 20 ff f7 a6 fd 10 bd 00 00 01 00 01 00 40 00 02 50 10 b5 00 22 01 21 80 20 ff f7 9a fd

10 bd 10 b5 04 46 00 2c 04 d0 01 21 80 20 ff f7 f5 fd 03 e0 00 21 80 20 ff f7 f0 fd 10 bd 10 b5

02 22 00 21 40 20 ff f7 85 fd 10 bd 03 48 04 49 88 60 00 20 03 49 48 71 70 47 00 00 10 00 10 00

40 00 02 50 00 00 03 50 00 20 02 49 48 70 01 20 48 71 70 47 00 00 03 50 00 28 03 d0 01 21 03 4a

51 70 02 e0 00 21 01 4a 51 70 70 47 00 00 03 50 10 b5 01 22 00 21 20 20 ff f7 5c fd 10 bd 10 b5

00 21 20 20 ff f7 ba fd 00 22 01 21 20 20 ff f7 51 fd 10 bd 10 b5 04 46 00 2c 04 d0 01 21 20 20

ff f7 ac fd 03 e0 00 21 20 20 ff f7 a7 fd 10 bd 30 b5 03 46 10 48 04 78 10 48 00 78 98 42 01 dd

0e 48 03 70 0e 48 01 70 0e 48 02 70 91 42 00 da 0a 46 0a 48 00 78 90 42 02 dd 07 48 02 70 03 e0

06 48 00 78 04 4d 28 70 03 48 00 78 84 42 01 d0 05 20 30 bd 00 20 fc e7 59 01 00 20 5a 01 00 20

32 01 00 20 33 01 00 20 10 b5 04 46 00 f0 a4 fa 00 20 fe f7 05 ff ff f7 89 ff 20 46 00 f0 54 f8

00 f0 02 f8 10 bd 00 00 01 48 02 49 08 60 70 47 b9 fd 00 00 40 00 01 50 10 b5 07 48 00 78 02 28

09 d0 05 48 00 78 01 28 03 d1 02 20 02 49 08 70 01 e0 ff f7 e9 ff 10 bd 61 01 00 20 10 b5 00 24

ff f7 48 ff 00 bf 0d e0 00 20 ff f7 4a ff 01 20 fe f7 b6 fa 01 20 ff f7 44 ff 03 20 fe f7 b0 fa

60 1c c4 b2 1e 2c ef db 10 bd 08 b5 03 21 68 46 01 70 00 21 41 70 03 21 81 70 01 21 c1 70 fd f7

a5 fb 01 22 7d 21 c9 01 00 20 ff f7 d7 fe 08 bd 10 b5 00 20 ff f7 e2 fe 10 bd 10 b5 00 20 ff f7

c1 fe 04 46 20 46 10 bd fe b5 05 46 00 27 00 f0 43 fa 01 95 00 20 3e 49 08 70 ff f7 50 ff fe f7

75 fa 00 20 ff f7 56 ff fe f7 50 fa 01 20 ff f7 51 ff 00 24 1f e0 37 48 00 78 00 28 03 d0 58 2d

01 d1 ff f7 13 ff 00 f0 27 fa 00 bf 30 48 00 78 00 28 fb d0 00 f0 20 fa 06 20 01 1b 01 98 08 41

c0 07 c0 0f 00 90 00 98 ff f7 34 ff 00 20 28 49 08 70 60 1c c4 b2 07 2c dd db 00 f0 0d fa 00 24

28 e0 24 48 00 78 00 28 03 d0 58 2d 01 d1 ff f7 ed fe 00 f0 01 fa 00 bf 1d 48 00 78 00 28 fb d0

00 f0 fa f9 00 2c 03 d1 ff f7 02 ff fe f7 2e fa 00 20 17 49 08 70 fe f7 6f fe 06 46 06 2c 07 d0

00 2c 05 d0 05 20 01 1b 30 46 88 40 38 43 c7 b2 60 1c c4 b2 07 2c d4 db 00 f0 de f9 00 bf 0c 48

00 78 00 28 fb d0 00 f0 d7 f9 ff f7 e8 fe fe f7 0d fa 00 20 ff f7 ee fe 00 20 05 49 08 70 fe f7

e5 f9 fe f7 e3 f9 00 f0 c7 f9 38 46 fe bd 00 00 11 01 00 20 10 01 00 20 fe b5 05 46 00 27 00 f0

bb f9 01 95 00 20 3c 49 08 70 ff f7 c8 fe fe f7 ed f9 00 20 ff f7 ce fe fe f7 c8 f9 01 20 ff f7

c9 fe 00 24 1f e0 35 48 00 78 00 28 03 d0 58 2d 01 d1 ff f7 8b fe 00 f0 9f f9 00 bf 2e 48 00 78

00 28 fb d0 00 f0 98 f9 06 20 01 1b 01 98 08 41 c0 07 c0 0f 00 90 00 98 ff f7 ac fe 00 20 26 49

08 70 60 1c c4 b2 07 2c dd db 00 f0 85 f9 00 24 24 e0 22 48 00 78 00 28 03 d0 58 2d 01 d1 ff f7

65 fe 00 f0 79 f9 00 bf 1b 48 00 78 00 28 fb d0 00 f0 72 f9 00 2c 03 d1 ff f7 7a fe fe f7 a6 f9

00 20 15 49 08 70 fe f7 e7 fd 06 46 06 20 01 1b 30 46 88 40 38 43 c7 b2 60 1c c4 b2 07 2c d8 db

00 f0 5a f9 00 bf 0c 48 00 78 00 28 fb d0 00 f0 53 f9 ff f7 64 fe fe f7 89 f9 00 20 ff f7 6a fe

00 20 05 49 08 70 fe f7 61 f9 fe f7 5f f9 00 f0 43 f9 38 46 fe bd 00 00 11 01 00 20 10 01 00 20

00 20 30 49 08 70 30 49 08 70 30 49 08 70 30 49 08 70 30 49 08 70 30 49 08 70 30 49 08 70 30 49

08 70 30 49 08 70 01 20 2f 49 08 70 00 20 48 70 88 70 2e 49 08 70 2e 49 08 70 2e 49 08 70 2e 49

08 70 03 20 2d 49 08 70 00 20 2d 49 08 70 2d 49 08 70 2d 49 08 70 2d 49 08 80 40 1e 2c 49 08 80

00 20 2c 49 08 70 2c 49 08 70 49 20 2b 49 08 70 2b 49 08 70 00 20 2b 49 08 70 2b 49 08 70 2b 49

08 70 49 20 2a 49 08 70 2a 49 08 70 01 20 2a 49 08 70 2a 49 08 70 00 20 29 49 08 70 29 49 08 70

02 20 29 49 08 70 03 20 28 49 08 70 00 20 28 49 08 70 28 49 08 70 28 49 08 70 28 49 08 70 28 49

08 70 70 47 10 01 00 20 17 01 00 20 18 01 00 20 12 01 00 20 13 01 00 20 14 01 00 20 15 01 00 20

16 01 00 20 21 01 00 20 84 01 00 20 22 01 00 20 24 01 00 20 25 01 00 20 26 01 00 20 27 01 00 20

28 01 00 20 29 01 00 20 2a 01 00 20 2c 01 00 20 2e 01 00 20 30 01 00 20 31 01 00 20 32 01 00 20

33 01 00 20 34 01 00 20 37 01 00 20 58 01 00 20 59 01 00 20 5a 01 00 20 5b 01 00 20 5c 01 00 20

5d 01 00 20 5e 01 00 20 5f 01 00 20 60 01 00 20 61 01 00 20 66 01 00 20 0a 01 00 20 67 01 00 20

0b 01 00 20 f8 b5 05 46 00 24 00 26 00 27 28 46 ff f7 8e fa 04 46 1c 48 00 68 24 1a 1b 48 00 68

e1 21 09 01 88 42 01 da 19 4e 77 00 17 48 00 68 18 49 88 42 02 da 16 4e 77 00 1b e0 13 48 00 68

14 49 64 31 88 42 02 da 11 4e 77 00 12 e0 0f 48 00 68 7d 21 49 01 88 42 02 da 0d 4e 77 00 09 e0

0a 48 00 68 0c 49 88 42 02 da 09 4e 77 00 01 e0 07 4e 77 00 b4 42 01 da 00 20 f8 bd bc 42 01 dd

02 20 fa e7 01 20 f8 e7 68 01 00 20 0c 01 00 20 22 02 00 00 74 0e 00 00 04 10 00 00 fe b5 06 46

0c 46 01 21 44 20 fe f7 4d ff 02 90 02 98 04 28 13 d1 15 48 00 68 fc f7 d1 ff 13 49 01 90 09 68

08 19 fc f7 cb ff 31 46 00 90 fc f7 ba fd 07 46 01 99 fc f7 f3 fd 05 46 14 e0 0b 48 00 68 fc f7

bd ff 09 49 01 90 09 68 09 19 08 46 c8 38 fc f7 b5 ff 31 46 00 90 fc f7 a4 fd 07 46 01 99 fc f7

dd fd 05 46 28 46 fe bd 80 01 00 20 10 b5 01 21 00 20 ff f7 a3 fc 10 bd 10 b5 ff f7 99 fc 10 bd

00 00 00 01 01 01 00 01 00 00 01 01 01 00 00 00 00 01 00 01 00 01 01 00 00 01 01 00 00 00 01 00

01 00 00 01 00 00 01 01 01 00 00 00 00 01 00 01 00 01 01 00 00 01 01 00 00 01 00 01 00 00 00 01

00 00 01 01 01 00 00 00 01 01 01 01 00 01 01 00 01 00 00 01 00 00 00 01 00 01 01 01 01 00 01 01

00 00 00 01 01 01 01 00 00 01 00 00 01 00 00 01 00 01 01 00 00 01 00 01 00 00 01 01 01 00 00 01

00 01 00 00 00 01 00 01 00 00 01 00 00 00 01 01 01 01 00 01 01 00 01 00 00 01 00 00 00 01 00 01

01 01 01 00 01 01 00 00 00 01 01 01 01 00 00 01 00 00 01 00 00 01 00 01 01 00 00 01 00 01 00 00

01 01 01 00 00 01 00 01 00 00 00 01 00 01 00 00 01 00 00 00 01 01 01 01 00 01 01 00 01 00 00 01

00 00 00 01 01 00 01 01 01 00 01 01 00 00 00 00 00 01 01 00 01 01 01 00 01 01 00 00 00 00 00 00

00 00 00 00 00 00 00 00 00 00 00 00 00 00 00 00 00 00 00 00 00 00 00 00 00 00 00 00 00 00 00 00

00 00 00 00 00 00 00 00 00 00 00 00 00 00 00 00 00 00 00 00 64 38 00 21 00 01 00 20 84 00 00 00

aa 0b 00 21 00 00 00 00 00 00 00 00 00 00 00 00 00 00 00 00 00 00 00 00 00 00 00 00 00 00 00 00

00 00 00 00 00 00 00 00 00 00 00 00 00 00 00 00 00 00 00 00 00 00 00 00 00 00 00 00 00 00 00 00

00 00 00 00 00 00 00 00 00 00 00 00 00 00 00 00 00 00 00 00 00 00 00 00 00 00 00 00 00 00 00 00

00 00 00 00 00 00 00 00 00 00 00 00 00 00 00 00 00 00 00 00 00 00 00 00 00 00 00 00 00 00 00 00

00 00 00 00 00 00 00 00 00 00 00 00 00 00 00 00 00 00 00 00 00 00 00 00 00 00 00 00 00 00 00 00

00 00 00 00 00 00 00 00 00 00 00 00 00 00 00 00 00 00 00 00 00 00 00 00 00 00 00 00 00 00 00 00

00 00 00 00 00 00 00 00 00 00 00 00 00 00 00 00 00 00 00 00 00 02 01 01 02 07 03 fe d2 34 55 34
		];

		qcom,svooc_0_to_50_little_cold_stop_cur = <1000>;
		qcom,svooc_0_to_50_cold_stop_cur = <1000>;
		qcom,svooc_0_to_50_little_cool_stop_cur = <1100>;
		qcom,svooc_0_to_50_normal_low_stop_cur = <1100>;
		qcom,svooc_0_to_50_normal_high_stop_cur = <1300>;
		qcom,svooc_0_to_50_warm_stop_cur = <1300>;

		qcom,svooc_51_to_75_little_cold_stop_cur = <1000>;
		qcom,svooc_51_to_75_cold_stop_cur = <1000>;
		qcom,svooc_51_to_75_little_cool_stop_cur = <1000>;
		qcom,svooc_51_to_75_normal_low_stop_cur = <1100>;
		qcom,svooc_51_to_75_normal_high_stop_cur = <1300>;

		qcom,svooc_76_to_85_little_cold_stop_cur = <1000>;
		qcom,svooc_76_to_85_cold_stop_cur = <1000>;
		qcom,svooc_76_to_85_little_cool_stop_cur = <1000>;
		qcom,svooc_76_to_85_normal_low_stop_cur = <1100>;
		qcom,svooc_76_to_85_normal_high_stop_cur = <1300>;

		qcom,svooc_86_to_90_little_cold_stop_cur = <1000>;
		qcom,svooc_86_to_90_cold_stop_cur = <1000>;
		qcom,svooc_86_to_90_little_cool_stop_cur = <1000>;
		qcom,svooc_86_to_90_normal_low_stop_cur = <1100>;
		qcom,svooc_86_to_90_normal_high_stop_cur = <1300>;

		qcom,vooc-max-input-volt-support = <10000>;     //10V
		qcom,vooc-max-input-current-support = <6500>;   //6A
		vooc_charge_strategy_30w {
			strategy_1 {
				capacity_range = <0 75>;
				temp_range = <120 160>;
				input_current = <4000 4450 0
												3000 4470 0
												2000 4480 0>;
				};
			strategy_2 {
				capacity_range = <0 75>;
				temp_range = <160 410>;
				input_current = <6000 4200 900
												5000 4200 0
												4500 4450 0
												4000 4450 0
												3000 4470 0
												2000 4480 0>;
			};
			strategy_3 {
				capacity_range = <0 75>;
				temp_range = <410 420>;
				input_current = <4000 4470 0
												2000 4480 0>;
			};
			strategy_4 {
				capacity_range = <0 75>;
				temp_range = <420 425>;
				input_current = <4000 4480 0>;
			};
			strategy_5 {
				capacity_range = <0 75>;
				temp_range = <425 435>;
				input_current = <3000 4480 0>;
			};
		};

		vooc_charge_strategy_65w {
			strategy_1 {
				capacity_range = <0 50>;
				temp_range = <120 160>;
				input_current = <6000 4200 0
												4000 4454 0
												2000 4494 0
												1500 4500 0>;
			};
			strategy_2 {
				capacity_range = <0 50>;
				temp_range = <160 370>;
				input_current = <6500 4200 0
												6000 4250 300
												5500 4300 400
												4500 4454 780
												3500 4454 0
												2000 4494 0
												1500 4500 0>;
			};
			strategy_3 {
				capacity_range = <0 90>;
				temp_range = <370 430>;
				input_current = <6500 4200 0
												6000 4250 300
												5500 4300 400
												4500 4454 780
												3500 4454 0
												2000 4494 0
												1600 4500 0>;
			};
		};
		svooc_charge_curve {
			strategy_soc_0_to_50 {
				strategy_temp_little_cold =	<4184 20 10 0
								 4424 15 10 0
								 4430 10 10 1>;
				strategy_temp_cool =		<4184 25 15 0
								 4424 20 10 0
								 4430 10 10 1>;
				strategy_temp_little_cool = 	<4184 50 35 0
								 4454 40 25 0
								 4484 30 11 0
								 4490 11 11 1>;
				strategy_temp_normal_low =	<4134 73 55 0
								 4184 60 45 0
								 4224 50 35 0
								 4454 40 25 0
								 4484 30 11 0
								 4490 11 11 1>;
				strategy_temp_normal_high =	<4134 73 55 0
								 4184 60 45 0
								 4224 50 35 0
								 4454 40 25 0
								 4484 30 13 0
								 4490 13 13 1>;
				strategy_temp_warm =	<4130 13 13 1>;
			};

			strategy_soc_50_to_75 {
				strategy_temp_little_cold =	<4424 15 10 0
								 4430 10 10 1>;
				strategy_temp_cool =		<4424 20 10 0
								 4430 10 10 1>;
				strategy_temp_little_cool =	<4454 40 25 0
								 4484 30 10 0
								 4490 10 10 1>;
				strategy_temp_normal_low =	<4454 40 25 0
								 4484 30 11 0
								 4490 11 11 1>;
				strategy_temp_normal_high =	<4224 45 35 0
								 4454 40 25 0
								 4484 30 13 0
								 4490 13 13 1>;
			};

			strategy_soc_75_to_85 {
				strategy_temp_little_cold = 	<4430 10 10 0>;
				strategy_temp_cool =		<4424 15 10 0
								 4430 10 10 1>;
				strategy_temp_little_cool =	<4484 25 10 0
								 4490 10 10 1>;
				strategy_temp_normal_low =	<4484 30 11 0
								 4490 11 11 1>;
				strategy_temp_normal_high =	<4484 30 13 0
								 4490 13 13 1>;
			};

			strategy_soc_85_to_90 {
				strategy_temp_little_cold = 	<4430 10 10 1>;
				strategy_temp_cool =		<4430 10 10 1>;
				strategy_temp_little_cool =	<4484 15 10 0
								 4490 10 10 1>;
				strategy_temp_normal_low =	<4484 20 11 0
								 4490 11 11 1>;
				strategy_temp_normal_high =	<4484 20 13 0
								 4490 13 13 1>;
			};
		};
	};
};

&i2c11 {
	status = "okay";
	clock-frequency = <100000>;

	charge_pump-divider@68 {
		status = "okay";
		compatible = "oplus,charge_pump-divider";
		reg = <0x68 0>;
		oplus,charge_pump-hwid-gpio = <&pio 185 0>;
		pinctrl-names = "charge_pump_hwid_active", "charge_pump_hwid_sleep", "charge_pump_hwid_default";
		pinctrl-0 = <&charge_pump_hwid_active>;
		pinctrl-1 = <&charge_pump_hwid_sleep>;
		pinctrl-2 = <&charge_pump_hwid_default>;
	};

	mp2650-charger@5c {
		status = "okay";
		compatible = "oplus,mp2650-charger";
		reg = <0x5c 0>;

		qcom,mps_otg_en-gpio = <&pio 129 0x00>;
		pinctrl-names = "mps_otg_en_active", "mps_otg_en_sleep", "mps_otg_en_default";
		pinctrl-0 = <&mps_otg_en_active>;
		pinctrl-1 = <&mps_otg_en_sleep>;
		pinctrl-2 = <&mps_otg_en_default>;
	};
};

&pio {
	charger_pins_default: eint0default {
	};

	charger_pins_eint_output0: charger_gpio_as_output_low {
		pins_cmd_dat {
			pinmux = <PINMUX_GPIO192__FUNC_GPIO192>;
			slew-rate = <1>;
			output-low;
		};
	};

	charger_pins_eint_output1: charger_gpio_as_output_high {
		pins_cmd_dat {
			pinmux = <PINMUX_GPIO192__FUNC_GPIO192>;
			slew-rate = <1>;
			output-high;
		};
	};

	ship_sleep_gpio: ship_sleep {
		pins_cmd_dat {
			pinmux = <PINMUX_GPIO27__FUNC_GPIO27>;
			slew-rate = <1>;
			output-low;
		};
	};

	ship_active_gpio: ship_active {
		pins_cmd_dat {
			pinmux = <PINMUX_GPIO27__FUNC_GPIO27>;
			slew-rate = <1>;
			output-high;
		};
	};

	dischg_enable: dischg_enable {
		pins_cmd_dat {
			pinmux = <PINMUX_GPIO51__FUNC_GPIO51>;
			output-enable;
			bias-pull-up = <MTK_PUPD_SET_R1R0_01>;
			output-high;
		};
	};

	dischg_disable: dischg_disable {
		pins_cmd_dat {
			pinmux = <PINMUX_GPIO51__FUNC_GPIO51>;
			output-enable;
			bias-pull-down = <MTK_PUPD_SET_R1R0_01>;
			output-low;
		};
	};

	vooc_asic_id_active: vooc_asic_id_active {
		pins_cmd_dat {
			pinmux = <PINMUX_GPIO187__FUNC_GPIO187>;
			input-enable;
			slew-rate = <0>;
			bias-pull-up;
		};
	};

	vooc_asic_id_sleep: vooc_asic_id_sleep {
		pins_cmd_dat {
			pinmux = <PINMUX_GPIO187__FUNC_GPIO187>;
			input-enable;
			slew-rate = <0>;
			bias-pull-down;
		};
	};

	ccdetect_active: ccdetect_active {
		pins_cmd_dat {
			pinmux = <PINMUX_GPIO5__FUNC_GPIO5>;
			input-enable;
			slew-rate = <0>;
			bias-disable;
		};
	};

	ccdetect_sleep: ccdetect_sleep {
		pins_cmd_dat {
			pinmux = <PINMUX_GPIO5__FUNC_GPIO5>;
			input-enable;
			slew-rate = <0>;
			bias-disable;
		};
	};

	chgvin_enable: chgvin_enable {
		pins_cmd_dat {
			pinmux = <PINMUX_GPIO30__FUNC_GPIO30>;
			slew-rate = <1>;//0:input direction 1:output direction
			bias-pull-up;
			output-low;
		};
	};

	chgvin_disable: chgvin_disable {
		pins_cmd_dat {
			pinmux = <PINMUX_GPIO30__FUNC_GPIO30>;
			slew-rate = <1>;
			bias-pull-down;
			output-high;
		};
	};

	pmic_chgfunc_enable: pmic_chgfunc_enable {
		pins_cmd_dat {
			pinmux = <PINMUX_GPIO26__FUNC_GPIO26>;
			slew-rate = <1>;//0:input direction 1:output direction
			bias-pull-up;
			output-low;
		};
	};

	pmic_chgfunc_disable: pmic_chgfunc_disable {
		pins_cmd_dat {
			pinmux = <PINMUX_GPIO26__FUNC_GPIO26>;
			slew-rate = <1>;
			bias-pull-down;
			output-high;
		};
	};

	charging_switch1_active: charging_switch1_active {
		pins_cmd_dat {
			pinmux = <PINMUX_GPIO191__FUNC_GPIO191>;
			slew-rate = <1>;
			output-high;
		};
	};

	charging_switch1_sleep: charging_switch1_sleep {
		pins_cmd_dat {
			pinmux = <PINMUX_GPIO191__FUNC_GPIO191>;
			slew-rate = <1>;
			output-low;
		};
	};

	charging_switch1_ctr1_active: charging_switch1_ctr1_active {
		pins_cmd_dat {
			pinmux = <PINMUX_GPIO163__FUNC_GPIO163>;
			slew-rate = <1>;
			bias-pull-up;
		};
	};

	charging_switch1_ctr1_sleep: charging_switch1_ctr1_sleep {
		pins_cmd_dat {
			pinmux = <PINMUX_GPIO163__FUNC_GPIO163>;
			slew-rate = <1>;
			output-low;
		};
	};

	charging_clock_active: charging_clock_active {
		pins_cmd_dat {
			pinmux = <PINMUX_GPIO95__FUNC_GPIO95>;
			slew-rate = <0>;
			bias-pull-up;
		};
	};

	charging_clock_sleep: charging_clock_sleep {
		pins_cmd_dat {
			pinmux = <PINMUX_GPIO95__FUNC_GPIO95>;
			slew-rate = <0>;
			bias-pull-down;
		};
	};

	charging_data_active: charging_data_active {
		pins_cmd_dat {
			pinmux = <PINMUX_GPIO94__FUNC_GPIO94>;
			slew-rate = <0>;
			bias-pull-down;
		};
	};

	charging_data_sleep: charging_data_sleep {
		pins_cmd_dat {
			pinmux = <PINMUX_GPIO94__FUNC_GPIO94>;
			slew-rate = <0>;
			bias-pull-down;
		};
	};

	charging_reset_active: charging_reset_active {
		pins_cmd_dat {
			pinmux = <PINMUX_GPIO189__FUNC_GPIO189>;
			slew-rate = <1>;
			bias-pull-down;
		};
	};

	charging_reset_sleep: charging_reset_sleep {
		pins_cmd_dat {
			pinmux = <PINMUX_GPIO189__FUNC_GPIO189>;
			slew-rate = <1>;
			bias-pull-up;
		};
	};

	mps_otg_en_active: mps_otg_en_active {
		pins_cmd_dat {
			pinmux = <PINMUX_GPIO129__FUNC_GPIO129>;
			slew-rate = <1>;
			bias-pull-up;
		};
	};

	mps_otg_en_sleep: mps_otg_en_sleep {
		pins_cmd_dat {
			pinmux = <PINMUX_GPIO129__FUNC_GPIO129>;
			slew-rate = <1>;
			bias-pull-down;
		};
	};

	mps_otg_en_default: mps_otg_en_default {
		pins_cmd_dat {
			pinmux = <PINMUX_GPIO129__FUNC_GPIO129>;
			slew-rate = <1>;
			bias-pull-down;
		};
	};

	charge_pump_hwid_active: charge_pump_hwid_active {
		pins_cmd_dat {
			pinmux = <PINMUX_GPIO185__FUNC_GPIO185>;
			input-enable;
			slew-rate = <0>;
			bias-pull-up = <MTK_PUPD_SET_R1R0_10>;
		};
	};

	charge_pump_hwid_sleep: charge_pump_hwid_sleep {
		pins_cmd_dat {
			pinmux = <PINMUX_GPIO185__FUNC_GPIO185>;
			input-enable;
			slew-rate = <0>;
			bias-pull-down = <MTK_PUPD_SET_R1R0_10>;
		};
	};

	charge_pump_hwid_default: charge_pump_hwid_default {
		pins_cmd_dat {
			pinmux = <PINMUX_GPIO185__FUNC_GPIO185>;
			input-enable;
			slew-rate = <0>;
			bias-disable;
		};
	};
};

&lk_charger {
	charger_by_buckboost;
	support_tuv_authentication;
	support_new_charger_stander;
	support_sdp_screenoff;

	max_charger_voltage = <9900000>;
	usb_charger_current = <500000>;
	ac_charger_input_current = <2000000>;
	non_std_ac_charger_current = <2000000>;
	charging_host_charger_current = <1500000>;
	pd_charger_current = <2000000>;
	precharge_1_step_current = <300>;

	cold_bat_decidegc = <10>;  /*-10C~0C*/
	dcp_temp_cold_fastchg_current = <300>;
	usb_temp_cold_fastchg_current = <300>;
	cdp_temp_cold_fastchg_current = <300>;

	little_cold_bat_decidegc = <0>;    /*0C~5C*/
	dcp_temp_little_cold_fastchg_current = <500>;
	usb_temp_little_cold_fastchg_current = <300>;
	cdp_temp_little_cold_fastchg_current = <500>;

	cool_bat_decidegc = <5>;  /*5C~12C*/
	dcp_temp_cool_fastchg_current = <800>;
	usb_temp_cool_fastchg_current = <300>;
	cdp_temp_cool_fastchg_current = <800>;

	little_cool_bat_decidegc = <12>;  /*12C~16C*/
	dcp_temp_little_cool_fastchg_current = <840>;
	usb_temp_little_cool_fastchg_current = <300>;
	cdp_temp_little_cool_fastchg_current = <800>;

	normal_bat_decidegc = <16>;       /*16C~45C*/
	dcp_temp_normal_fastchg_current = <840>;
	usb_temp_normal_fastchg_current = <300>;
	cdp_temp_normal_fastchg_current = <800>;

	warm_bat_decidegc = <45>;    /*45C~53C*/
	dcp_temp_warm_fastchg_current = <840>;
	usb_temp_warm_fastchg_current = <300>;
	cdp_temp_warm_fastchg_current = <800>;

	hot_bat_decidegc = <53>;
};

&mt6360_pmu {
	core {
		sda_sizesel = <3>;
		sda_drvsrsel = <1>;
	};
	chg {
		support_hvdcp;
	};
};

&bat_gm30 {
	FUELGAGUE_APPLY = <(0)>;
	DISABLE_MTKBATTERY = <(1)>;
};

&i2c7 {
	pinctrl-names = "i2c-state", "output-low-state";
	pinctrl-0 = <&i2c7_i2c_state>;
	pinctrl-1 = <&i2c7_output_low_state>;
};
&pio {
	i2c7_i2c_state: i2c7_sda_i2c_state {
		pins_cmd_dat {
			pinmux = <PINMUX_GPIO125__FUNC_SDA7>;
			slew-rate = <0>;
			bias-disable;
		};
	};
	i2c7_output_low_state: i2c7_sda_output_low_state {
		pins_cmd_dat {
			pinmux = <PINMUX_GPIO125__FUNC_GPIO125>;
			slew-rate = <1>;
			output-low;
		};
	};
};

/* chagrge end */
